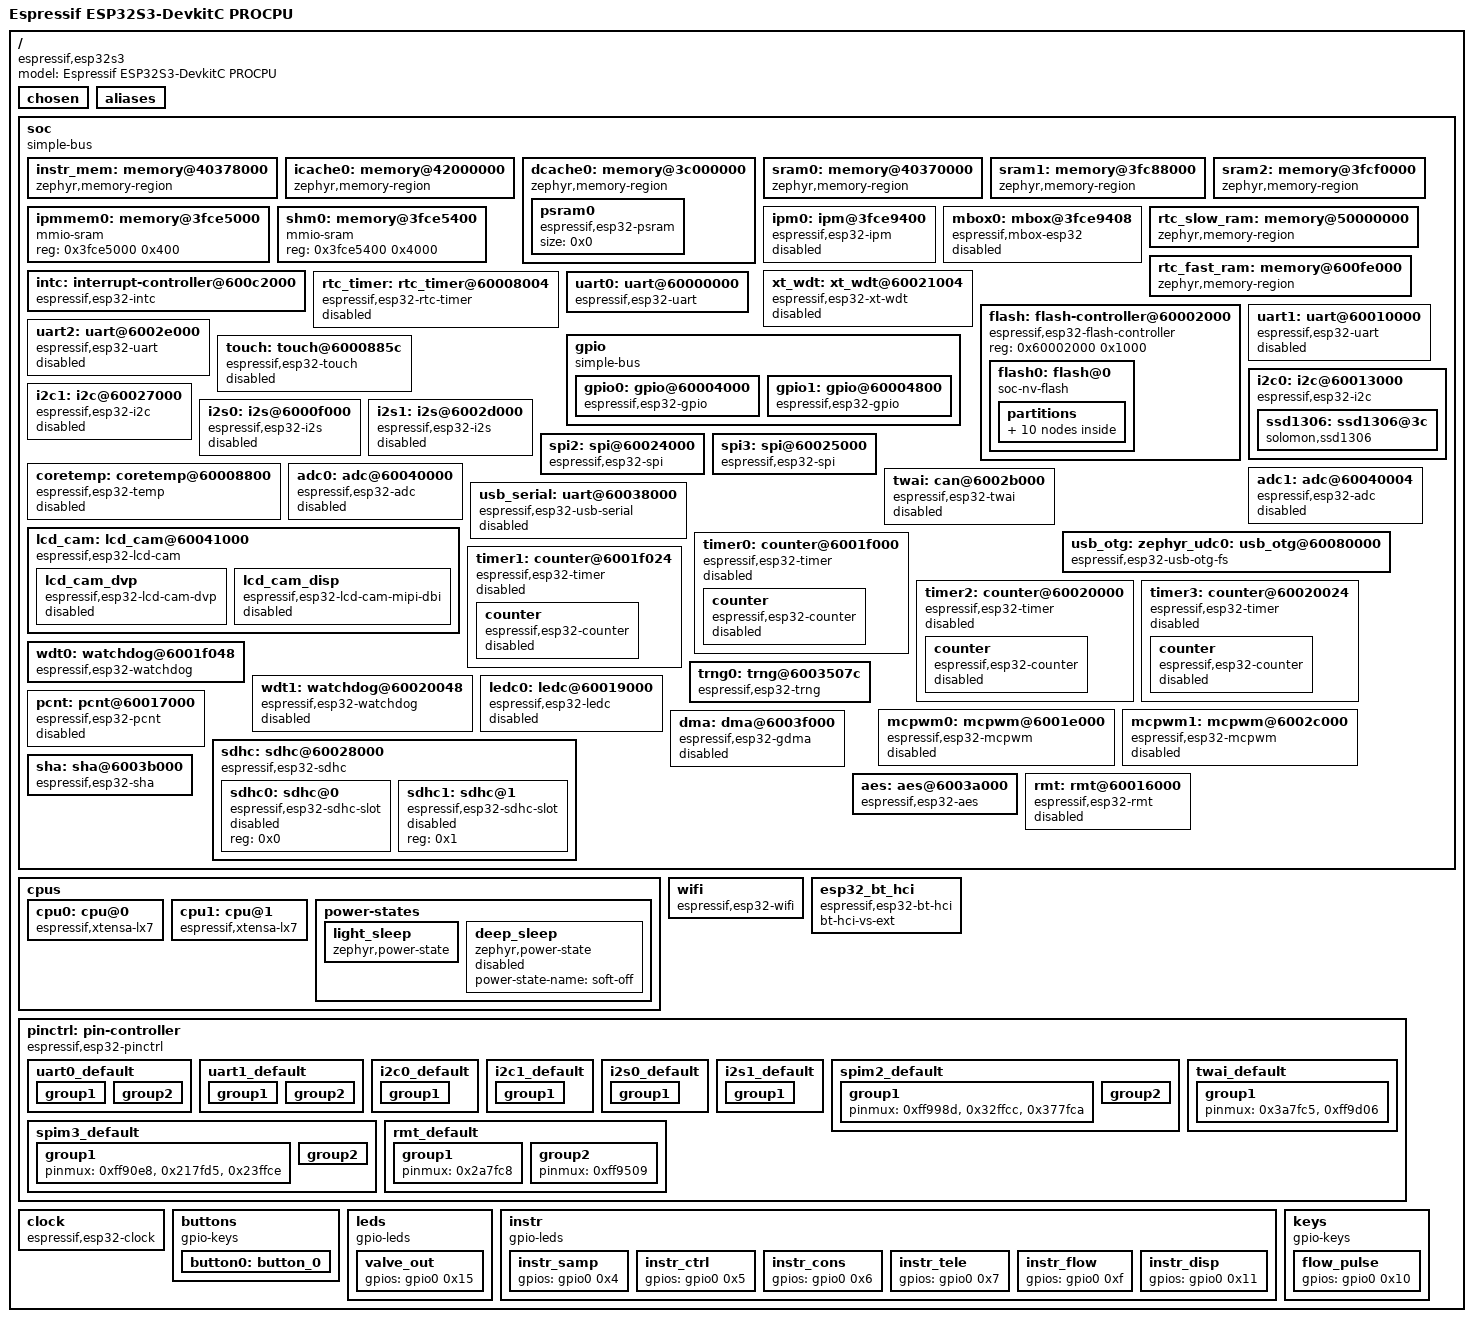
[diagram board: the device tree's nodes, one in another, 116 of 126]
/dts-v1/;

/* node '/' defined in zephyr/dts/common/skeleton.dtsi:9 */
/ {
	#address-cells = < 0x1 >;                   /* in zephyr/dts/common/skeleton.dtsi:10 */
	#size-cells = < 0x1 >;                      /* in zephyr/dts/common/skeleton.dtsi:11 */
	model = "Espressif ESP32S3-DevkitC PROCPU"; /* in zephyr/boards/espressif/esp32s3_devkitc/esp32s3_devkitc_procpu.dts:15 */
	compatible = "espressif,esp32s3";           /* in zephyr/boards/espressif/esp32s3_devkitc/esp32s3_devkitc_procpu.dts:16 */

	/* node '/chosen' defined in zephyr/dts/common/skeleton.dtsi:13 */
	chosen {
		zephyr,canbus = &twai;                    /* in zephyr/dts/xtensa/espressif/esp32s3/esp32s3_common.dtsi:22 */
		zephyr,entropy = &trng0;                  /* in zephyr/dts/xtensa/espressif/esp32s3/esp32s3_common.dtsi:23 */
		zephyr,flash-controller = &flash;         /* in zephyr/dts/xtensa/espressif/esp32s3/esp32s3_common.dtsi:24 */
		zephyr,sram = &sram1;                     /* in zephyr/boards/espressif/esp32s3_devkitc/esp32s3_devkitc_procpu.dts:26 */
		zephyr,console = &uart0;                  /* in zephyr/boards/espressif/esp32s3_devkitc/esp32s3_devkitc_procpu.dts:27 */
		zephyr,shell-uart = &uart0;               /* in zephyr/boards/espressif/esp32s3_devkitc/esp32s3_devkitc_procpu.dts:28 */
		zephyr,flash = &flash0;                   /* in zephyr/boards/espressif/esp32s3_devkitc/esp32s3_devkitc_procpu.dts:29 */
		zephyr,code-partition = &slot0_partition; /* in zephyr/boards/espressif/esp32s3_devkitc/esp32s3_devkitc_procpu.dts:30 */
		zephyr,bt-hci = &esp32_bt_hci;            /* in zephyr/boards/espressif/esp32s3_devkitc/esp32s3_devkitc_procpu.dts:31 */
	};

	/* node '/aliases' defined in zephyr/dts/common/skeleton.dtsi:15 */
	aliases {
		die-temp0 = &coretemp; /* in zephyr/dts/xtensa/espressif/esp32s3/esp32s3_common.dtsi:18 */
		i2c-0 = &i2c0;         /* in zephyr/boards/espressif/esp32s3_devkitc/esp32s3_devkitc_procpu.dts:19 */
		watchdog0 = &wdt0;     /* in zephyr/boards/espressif/esp32s3_devkitc/esp32s3_devkitc_procpu.dts:20 */
		uart-0 = &uart0;       /* in zephyr/boards/espressif/esp32s3_devkitc/esp32s3_devkitc_procpu.dts:21 */
		sw0 = &button0;        /* in zephyr/boards/espressif/esp32s3_devkitc/esp32s3_devkitc_procpu.dts:22 */
		led0 = &valve_out;     /* in ../4101137-real-time-systems/firmware/superloop/boards/esp32s3_devkitc_esp32s3_procpu.overlay:16 */
	};

	/* node '/soc' defined in zephyr/dts/xtensa/xtensa.dtsi:10 */
	soc {
		#address-cells = < 0x1 >;  /* in zephyr/dts/xtensa/espressif/esp32s3/esp32s3_common.dtsi:97 */
		#size-cells = < 0x1 >;     /* in zephyr/dts/xtensa/espressif/esp32s3/esp32s3_common.dtsi:98 */
		compatible = "simple-bus"; /* in zephyr/dts/xtensa/espressif/esp32s3/esp32s3_common.dtsi:99 */
		ranges;                    /* in zephyr/dts/xtensa/espressif/esp32s3/esp32s3_common.dtsi:100 */

		/* node '/soc/memory@40378000' defined in zephyr/dts/xtensa/espressif/esp32s3/esp32s3_common.dtsi:102 */
		instr_mem: memory@40378000 {
			compatible = "zephyr,memory-region"; /* in zephyr/dts/xtensa/espressif/esp32s3/esp32s3_common.dtsi:103 */
			reg = < 0x40378000 0x68000 >;        /* in zephyr/dts/xtensa/espressif/esp32s3/esp32s3_common.dtsi:104 */
			zephyr,memory-region = "IRAM";       /* in zephyr/dts/xtensa/espressif/esp32s3/esp32s3_common.dtsi:105 */
		};

		/* node '/soc/memory@42000000' defined in zephyr/dts/xtensa/espressif/esp32s3/esp32s3_common.dtsi:108 */
		icache0: memory@42000000 {
			compatible = "zephyr,memory-region"; /* in zephyr/dts/xtensa/espressif/esp32s3/esp32s3_common.dtsi:109 */
			reg = < 0x42000000 0x2000000 >;      /* in zephyr/dts/xtensa/espressif/esp32s3/esp32s3_common.dtsi:110 */
			zephyr,memory-region = "ICACHE0";    /* in zephyr/dts/xtensa/espressif/esp32s3/esp32s3_common.dtsi:111 */
		};

		/* node '/soc/memory@3c000000' defined in zephyr/dts/xtensa/espressif/esp32s3/esp32s3_common.dtsi:114 */
		dcache0: memory@3c000000 {
			compatible = "zephyr,memory-region"; /* in zephyr/dts/xtensa/espressif/esp32s3/esp32s3_common.dtsi:115 */
			reg = < 0x3c000000 0x2000000 >;      /* in zephyr/dts/xtensa/espressif/esp32s3/esp32s3_common.dtsi:116 */
			zephyr,memory-region = "DCACHE0";    /* in zephyr/dts/xtensa/espressif/esp32s3/esp32s3_common.dtsi:117 */

			/* node '/soc/memory@3c000000/psram0' defined in zephyr/dts/xtensa/espressif/esp32s3/esp32s3_common.dtsi:119 */
			psram0: psram0 {
				compatible = "espressif,esp32-psram"; /* in zephyr/dts/xtensa/espressif/esp32s3/esp32s3_common.dtsi:120 */
				size = < 0x0 >;                       /* in zephyr/dts/xtensa/espressif/esp32s3/esp32s3_common.dtsi:121 */
			};
		};

		/* node '/soc/memory@40370000' defined in zephyr/dts/xtensa/espressif/esp32s3/esp32s3_common.dtsi:125 */
		sram0: memory@40370000 {
			compatible = "zephyr,memory-region",
			             "mmio-sram";            /* in zephyr/dts/xtensa/espressif/esp32s3/esp32s3_common.dtsi:126 */
			reg = < 0x40370000 0x8000 >;         /* in zephyr/dts/xtensa/espressif/esp32s3/esp32s3_common.dtsi:127 */
			zephyr,memory-region = "SRAM0";      /* in zephyr/dts/xtensa/espressif/esp32s3/esp32s3_common.dtsi:128 */
		};

		/* node '/soc/memory@3fc88000' defined in zephyr/dts/xtensa/espressif/esp32s3/esp32s3_common.dtsi:131 */
		sram1: memory@3fc88000 {
			compatible = "zephyr,memory-region",
			             "mmio-sram";            /* in zephyr/dts/xtensa/espressif/esp32s3/esp32s3_common.dtsi:132 */
			reg = < 0x3fc88000 0x68000 >;        /* in zephyr/dts/xtensa/espressif/esp32s3/esp32s3_common.dtsi:133 */
			zephyr,memory-region = "SRAM1";      /* in zephyr/dts/xtensa/espressif/esp32s3/esp32s3_common.dtsi:134 */
		};

		/* node '/soc/memory@3fcf0000' defined in zephyr/dts/xtensa/espressif/esp32s3/esp32s3_common.dtsi:137 */
		sram2: memory@3fcf0000 {
			compatible = "zephyr,memory-region",
			             "mmio-sram";            /* in zephyr/dts/xtensa/espressif/esp32s3/esp32s3_common.dtsi:138 */
			reg = < 0x3fcf0000 0x10000 >;        /* in zephyr/dts/xtensa/espressif/esp32s3/esp32s3_common.dtsi:139 */
			zephyr,memory-region = "SRAM2";      /* in zephyr/dts/xtensa/espressif/esp32s3/esp32s3_common.dtsi:140 */
		};

		/* node '/soc/memory@3fce5000' defined in zephyr/dts/xtensa/espressif/esp32s3/esp32s3_common.dtsi:143 */
		ipmmem0: memory@3fce5000 {
			compatible = "mmio-sram";   /* in zephyr/dts/xtensa/espressif/esp32s3/esp32s3_common.dtsi:144 */
			reg = < 0x3fce5000 0x400 >; /* in zephyr/dts/xtensa/espressif/esp32s3/esp32s3_common.dtsi:145 */
			phandle = < 0x1 >;          /* in zephyr/dts/xtensa/espressif/esp32s3/esp32s3_common.dtsi:157 */
		};

		/* node '/soc/memory@3fce5400' defined in zephyr/dts/xtensa/espressif/esp32s3/esp32s3_common.dtsi:148 */
		shm0: memory@3fce5400 {
			compatible = "mmio-sram";    /* in zephyr/dts/xtensa/espressif/esp32s3/esp32s3_common.dtsi:149 */
			reg = < 0x3fce5400 0x4000 >; /* in zephyr/dts/xtensa/espressif/esp32s3/esp32s3_common.dtsi:150 */
		};

		/* node '/soc/ipm@3fce9400' defined in zephyr/dts/xtensa/espressif/esp32s3/esp32s3_common.dtsi:153 */
		ipm0: ipm@3fce9400 {
			compatible = "espressif,esp32-ipm"; /* in zephyr/dts/xtensa/espressif/esp32s3/esp32s3_common.dtsi:154 */
			reg = < 0x3fce9400 0x8 >;           /* in zephyr/dts/xtensa/espressif/esp32s3/esp32s3_common.dtsi:155 */
			status = "disabled";                /* in zephyr/dts/xtensa/espressif/esp32s3/esp32s3_common.dtsi:156 */
			shared-memory = < &ipmmem0 >;       /* in zephyr/dts/xtensa/espressif/esp32s3/esp32s3_common.dtsi:157 */
			shared-memory-size = < 0x400 >;     /* in zephyr/dts/xtensa/espressif/esp32s3/esp32s3_common.dtsi:158 */
			interrupts = < 0x4f 0x0 0x0 >,
			             < 0x50 0x0 0x0 >;      /* in zephyr/dts/xtensa/espressif/esp32s3/esp32s3_common.dtsi:159 */
			interrupt-parent = < &intc >;       /* in zephyr/dts/xtensa/espressif/esp32s3/esp32s3_common.dtsi:161 */
		};

		/* node '/soc/mbox@3fce9408' defined in zephyr/dts/xtensa/espressif/esp32s3/esp32s3_common.dtsi:164 */
		mbox0: mbox@3fce9408 {
			compatible = "espressif,mbox-esp32"; /* in zephyr/dts/xtensa/espressif/esp32s3/esp32s3_common.dtsi:165 */
			reg = < 0x3fce9408 0x8 >;            /* in zephyr/dts/xtensa/espressif/esp32s3/esp32s3_common.dtsi:166 */
			status = "disabled";                 /* in zephyr/dts/xtensa/espressif/esp32s3/esp32s3_common.dtsi:167 */
			shared-memory = < &ipmmem0 >;        /* in zephyr/dts/xtensa/espressif/esp32s3/esp32s3_common.dtsi:168 */
			shared-memory-size = < 0x400 >;      /* in zephyr/dts/xtensa/espressif/esp32s3/esp32s3_common.dtsi:169 */
			interrupts = < 0x4f 0x0 0x0 >,
			             < 0x50 0x0 0x0 >;       /* in zephyr/dts/xtensa/espressif/esp32s3/esp32s3_common.dtsi:170 */
			interrupt-parent = < &intc >;        /* in zephyr/dts/xtensa/espressif/esp32s3/esp32s3_common.dtsi:172 */
			#mbox-cells = < 0x1 >;               /* in zephyr/dts/xtensa/espressif/esp32s3/esp32s3_common.dtsi:173 */
		};

		/* node '/soc/memory@50000000' defined in zephyr/dts/xtensa/espressif/esp32s3/esp32s3_common.dtsi:176 */
		rtc_slow_ram: memory@50000000 {
			compatible = "zephyr,memory-region",
			             "mmio-sram";              /* in zephyr/dts/xtensa/espressif/esp32s3/esp32s3_common.dtsi:177 */
			reg = < 0x50000000 0x2000 >;           /* in zephyr/dts/xtensa/espressif/esp32s3/esp32s3_common.dtsi:178 */
			zephyr,memory-region = "RTC_SLOW_RAM"; /* in zephyr/dts/xtensa/espressif/esp32s3/esp32s3_common.dtsi:179 */
		};

		/* node '/soc/memory@600fe000' defined in zephyr/dts/xtensa/espressif/esp32s3/esp32s3_common.dtsi:182 */
		rtc_fast_ram: memory@600fe000 {
			compatible = "zephyr,memory-region",
			             "mmio-sram";              /* in zephyr/dts/xtensa/espressif/esp32s3/esp32s3_common.dtsi:183 */
			reg = < 0x600fe000 0x2000 >;           /* in zephyr/dts/xtensa/espressif/esp32s3/esp32s3_common.dtsi:184 */
			zephyr,memory-region = "RTC_FAST_RAM"; /* in zephyr/dts/xtensa/espressif/esp32s3/esp32s3_common.dtsi:185 */
		};

		/* node '/soc/interrupt-controller@600c2000' defined in zephyr/dts/xtensa/espressif/esp32s3/esp32s3_common.dtsi:188 */
		intc: interrupt-controller@600c2000 {
			#interrupt-cells = < 0x3 >;          /* in zephyr/dts/xtensa/espressif/esp32s3/esp32s3_common.dtsi:189 */
			#address-cells = < 0x0 >;            /* in zephyr/dts/xtensa/espressif/esp32s3/esp32s3_common.dtsi:190 */
			compatible = "espressif,esp32-intc"; /* in zephyr/dts/xtensa/espressif/esp32s3/esp32s3_common.dtsi:191 */
			interrupt-controller;                /* in zephyr/dts/xtensa/espressif/esp32s3/esp32s3_common.dtsi:192 */
			reg = < 0x600c2000 0x1000 >;         /* in zephyr/dts/xtensa/espressif/esp32s3/esp32s3_common.dtsi:193 */
			status = "okay";                     /* in zephyr/dts/xtensa/espressif/esp32s3/esp32s3_common.dtsi:194 */
			phandle = < 0x2 >;                   /* in zephyr/dts/xtensa/espressif/esp32s3/esp32s3_common.dtsi:161 */
		};

		/* node '/soc/xt_wdt@60021004' defined in zephyr/dts/xtensa/espressif/esp32s3/esp32s3_common.dtsi:197 */
		xt_wdt: xt_wdt@60021004 {
			compatible = "espressif,esp32-xt-wdt"; /* in zephyr/dts/xtensa/espressif/esp32s3/esp32s3_common.dtsi:198 */
			reg = < 0x60021004 0x4 >;              /* in zephyr/dts/xtensa/espressif/esp32s3/esp32s3_common.dtsi:199 */
			clocks = < &clock 0xc >;               /* in zephyr/dts/xtensa/espressif/esp32s3/esp32s3_common.dtsi:200 */
			interrupts = < 0x27 0x0 0x0 >;         /* in zephyr/dts/xtensa/espressif/esp32s3/esp32s3_common.dtsi:201 */
			interrupt-parent = < &intc >;          /* in zephyr/dts/xtensa/espressif/esp32s3/esp32s3_common.dtsi:202 */
			status = "disabled";                   /* in zephyr/dts/xtensa/espressif/esp32s3/esp32s3_common.dtsi:203 */
		};

		/* node '/soc/rtc_timer@60008004' defined in zephyr/dts/xtensa/espressif/esp32s3/esp32s3_common.dtsi:206 */
		rtc_timer: rtc_timer@60008004 {
			reg = < 0x60008004 0xc >;                 /* in zephyr/dts/xtensa/espressif/esp32s3/esp32s3_common.dtsi:207 */
			compatible = "espressif,esp32-rtc-timer"; /* in zephyr/dts/xtensa/espressif/esp32s3/esp32s3_common.dtsi:208 */
			clocks = < &clock 0xc >;                  /* in zephyr/dts/xtensa/espressif/esp32s3/esp32s3_common.dtsi:209 */
			interrupts = < 0x27 0x0 0x0 >;            /* in zephyr/dts/xtensa/espressif/esp32s3/esp32s3_common.dtsi:210 */
			interrupt-parent = < &intc >;             /* in zephyr/dts/xtensa/espressif/esp32s3/esp32s3_common.dtsi:211 */
			status = "disabled";                      /* in zephyr/dts/xtensa/espressif/esp32s3/esp32s3_common.dtsi:212 */
		};

		/* node '/soc/flash-controller@60002000' defined in zephyr/dts/xtensa/espressif/esp32s3/esp32s3_common.dtsi:215 */
		flash: flash-controller@60002000 {
			compatible = "espressif,esp32-flash-controller"; /* in zephyr/dts/xtensa/espressif/esp32s3/esp32s3_common.dtsi:216 */
			reg = < 0x60002000 0x1000 >;                     /* in zephyr/dts/xtensa/espressif/esp32s3/esp32s3_common.dtsi:217 */
			#address-cells = < 0x1 >;                        /* in zephyr/dts/xtensa/espressif/esp32s3/esp32s3_common.dtsi:218 */
			#size-cells = < 0x1 >;                           /* in zephyr/dts/xtensa/espressif/esp32s3/esp32s3_common.dtsi:219 */
			ranges;                                          /* in zephyr/dts/xtensa/espressif/esp32s3/esp32s3_common.dtsi:220 */

			/* node '/soc/flash-controller@60002000/flash@0' defined in zephyr/dts/xtensa/espressif/esp32s3/esp32s3_common.dtsi:222 */
			flash0: flash@0 {
				compatible = "soc-nv-flash";   /* in zephyr/dts/xtensa/espressif/esp32s3/esp32s3_common.dtsi:223 */
				erase-block-size = < 0x1000 >; /* in zephyr/dts/xtensa/espressif/esp32s3/esp32s3_common.dtsi:224 */
				write-block-size = < 0x4 >;    /* in zephyr/dts/xtensa/espressif/esp32s3/esp32s3_common.dtsi:225 */
				#address-cells = < 0x1 >;      /* in zephyr/dts/xtensa/espressif/esp32s3/esp32s3_common.dtsi:226 */
				#size-cells = < 0x1 >;         /* in zephyr/dts/xtensa/espressif/esp32s3/esp32s3_common.dtsi:227 */
				reg = < 0x0 0x800000 >;        /* in zephyr/dts/xtensa/espressif/esp32s3/esp32s3_wroom_n8.dtsi:11 */
				ranges = < 0x0 0x0 0x800000 >; /* in zephyr/dts/xtensa/espressif/esp32s3/esp32s3_wroom_n8.dtsi:12 */

				/* node '/soc/flash-controller@60002000/flash@0/partitions' defined in zephyr/dts/vendor/espressif/partitions_0x0_amp_4M.dtsi:8 */
				partitions {
					ranges;                   /* in zephyr/dts/vendor/espressif/partitions_0x0_amp_4M.dtsi:9 */
					#address-cells = < 0x1 >; /* in zephyr/dts/vendor/espressif/partitions_0x0_amp_4M.dtsi:10 */
					#size-cells = < 0x1 >;    /* in zephyr/dts/vendor/espressif/partitions_0x0_amp_4M.dtsi:11 */

					/* node '/soc/flash-controller@60002000/flash@0/partitions/partition@0' defined in zephyr/dts/vendor/espressif/partitions_0x0_amp_4M.dtsi:13 */
					boot_partition: partition@0 {
						compatible = "zephyr,mapped-partition"; /* in zephyr/dts/vendor/espressif/partitions_0x0_amp_4M.dtsi:14 */
						label = "mcuboot";                      /* in zephyr/dts/vendor/espressif/partitions_0x0_amp_4M.dtsi:15 */
						reg = < 0x0 0x10000 >;                  /* in zephyr/dts/vendor/espressif/partitions_0x0_amp_4M.dtsi:16 */
					};

					/* node '/soc/flash-controller@60002000/flash@0/partitions/partition@10000' defined in zephyr/dts/vendor/espressif/partitions_0x0_amp_4M.dtsi:19 */
					sys_partition: partition@10000 {
						compatible = "zephyr,mapped-partition"; /* in zephyr/dts/vendor/espressif/partitions_0x0_amp_4M.dtsi:20 */
						label = "sys";                          /* in zephyr/dts/vendor/espressif/partitions_0x0_amp_4M.dtsi:21 */
						reg = < 0x10000 0x10000 >;              /* in zephyr/dts/vendor/espressif/partitions_0x0_amp_4M.dtsi:22 */
					};

					/* node '/soc/flash-controller@60002000/flash@0/partitions/partition@20000' defined in zephyr/dts/vendor/espressif/partitions_0x0_amp_4M.dtsi:25 */
					slot0_partition: partition@20000 {
						compatible = "zephyr,mapped-partition"; /* in zephyr/dts/vendor/espressif/partitions_0x0_amp_4M.dtsi:26 */
						label = "image-0";                      /* in zephyr/dts/vendor/espressif/partitions_0x0_amp_4M.dtsi:27 */
						reg = < 0x20000 0x150000 >;             /* in zephyr/dts/vendor/espressif/partitions_0x0_amp_4M.dtsi:28 */
					};

					/* node '/soc/flash-controller@60002000/flash@0/partitions/partition@170000' defined in zephyr/dts/vendor/espressif/partitions_0x0_amp_4M.dtsi:31 */
					slot1_partition: partition@170000 {
						compatible = "zephyr,mapped-partition"; /* in zephyr/dts/vendor/espressif/partitions_0x0_amp_4M.dtsi:32 */
						label = "image-1";                      /* in zephyr/dts/vendor/espressif/partitions_0x0_amp_4M.dtsi:33 */
						reg = < 0x170000 0x150000 >;            /* in zephyr/dts/vendor/espressif/partitions_0x0_amp_4M.dtsi:34 */
					};

					/* node '/soc/flash-controller@60002000/flash@0/partitions/partition@2c0000' defined in zephyr/dts/vendor/espressif/partitions_0x0_amp_4M.dtsi:37 */
					slot0_appcpu_partition: partition@2c0000 {
						compatible = "zephyr,mapped-partition"; /* in zephyr/dts/vendor/espressif/partitions_0x0_amp_4M.dtsi:38 */
						label = "image-0-appcpu";               /* in zephyr/dts/vendor/espressif/partitions_0x0_amp_4M.dtsi:39 */
						reg = < 0x2c0000 0x70000 >;             /* in zephyr/dts/vendor/espressif/partitions_0x0_amp_4M.dtsi:40 */
					};

					/* node '/soc/flash-controller@60002000/flash@0/partitions/partition@330000' defined in zephyr/dts/vendor/espressif/partitions_0x0_amp_4M.dtsi:43 */
					slot1_appcpu_partition: partition@330000 {
						compatible = "zephyr,mapped-partition"; /* in zephyr/dts/vendor/espressif/partitions_0x0_amp_4M.dtsi:44 */
						label = "image-1-appcpu";               /* in zephyr/dts/vendor/espressif/partitions_0x0_amp_4M.dtsi:45 */
						reg = < 0x330000 0x70000 >;             /* in zephyr/dts/vendor/espressif/partitions_0x0_amp_4M.dtsi:46 */
					};

					/* node '/soc/flash-controller@60002000/flash@0/partitions/partition@3a0000' defined in zephyr/dts/vendor/espressif/partitions_0x0_amp_4M.dtsi:49 */
					slot0_lpcore_partition: partition@3a0000 {
						compatible = "zephyr,mapped-partition"; /* in zephyr/dts/vendor/espressif/partitions_0x0_amp_4M.dtsi:50 */
						label = "image-0-lpcore";               /* in zephyr/dts/vendor/espressif/partitions_0x0_amp_4M.dtsi:51 */
						reg = < 0x3a0000 0x8000 >;              /* in zephyr/dts/vendor/espressif/partitions_0x0_amp_4M.dtsi:52 */
					};

					/* node '/soc/flash-controller@60002000/flash@0/partitions/partition@3a8000' defined in zephyr/dts/vendor/espressif/partitions_0x0_amp_4M.dtsi:55 */
					slot1_lpcore_partition: partition@3a8000 {
						compatible = "zephyr,mapped-partition"; /* in zephyr/dts/vendor/espressif/partitions_0x0_amp_4M.dtsi:56 */
						label = "image-1-lpcore";               /* in zephyr/dts/vendor/espressif/partitions_0x0_amp_4M.dtsi:57 */
						reg = < 0x3a8000 0x8000 >;              /* in zephyr/dts/vendor/espressif/partitions_0x0_amp_4M.dtsi:58 */
					};

					/* node '/soc/flash-controller@60002000/flash@0/partitions/partition@3b0000' defined in zephyr/dts/vendor/espressif/partitions_0x0_amp_4M.dtsi:61 */
					storage_partition: partition@3b0000 {
						compatible = "zephyr,mapped-partition"; /* in zephyr/dts/vendor/espressif/partitions_0x0_amp_4M.dtsi:62 */
						label = "storage";                      /* in zephyr/dts/vendor/espressif/partitions_0x0_amp_4M.dtsi:63 */
						reg = < 0x3b0000 0x30000 >;             /* in zephyr/dts/vendor/espressif/partitions_0x0_amp_4M.dtsi:64 */
					};

					/* node '/soc/flash-controller@60002000/flash@0/partitions/partition@3ff000' defined in zephyr/dts/vendor/espressif/partitions_0x0_amp_4M.dtsi:67 */
					coredump_partition: partition@3ff000 {
						compatible = "zephyr,mapped-partition"; /* in zephyr/dts/vendor/espressif/partitions_0x0_amp_4M.dtsi:68 */
						label = "coredump";                     /* in zephyr/dts/vendor/espressif/partitions_0x0_amp_4M.dtsi:69 */
						reg = < 0x3ff000 0x1000 >;              /* in zephyr/dts/vendor/espressif/partitions_0x0_amp_4M.dtsi:70 */
					};
				};
			};
		};

		/* node '/soc/uart@60000000' defined in zephyr/dts/xtensa/espressif/esp32s3/esp32s3_common.dtsi:232 */
		uart0: uart@60000000 {
			compatible = "espressif,esp32-uart"; /* in zephyr/dts/xtensa/espressif/esp32s3/esp32s3_common.dtsi:233 */
			reg = < 0x60000000 0x1000 >;         /* in zephyr/dts/xtensa/espressif/esp32s3/esp32s3_common.dtsi:234 */
			interrupts = < 0x1b 0x0 0x0 >;       /* in zephyr/dts/xtensa/espressif/esp32s3/esp32s3_common.dtsi:235 */
			interrupt-parent = < &intc >;        /* in zephyr/dts/xtensa/espressif/esp32s3/esp32s3_common.dtsi:236 */
			clocks = < &clock 0x65 >;            /* in zephyr/dts/xtensa/espressif/esp32s3/esp32s3_common.dtsi:237 */
			status = "okay";                     /* in zephyr/boards/espressif/esp32s3_devkitc/esp32s3_devkitc_procpu.dts:50 */
			current-speed = < 0x1c200 >;         /* in zephyr/boards/espressif/esp32s3_devkitc/esp32s3_devkitc_procpu.dts:51 */
			pinctrl-0 = < &uart0_default >;      /* in zephyr/boards/espressif/esp32s3_devkitc/esp32s3_devkitc_procpu.dts:52 */
			pinctrl-names = "default";           /* in zephyr/boards/espressif/esp32s3_devkitc/esp32s3_devkitc_procpu.dts:53 */
		};

		/* node '/soc/uart@60010000' defined in zephyr/dts/xtensa/espressif/esp32s3/esp32s3_common.dtsi:241 */
		uart1: uart@60010000 {
			compatible = "espressif,esp32-uart"; /* in zephyr/dts/xtensa/espressif/esp32s3/esp32s3_common.dtsi:242 */
			reg = < 0x60010000 0x1000 >;         /* in zephyr/dts/xtensa/espressif/esp32s3/esp32s3_common.dtsi:243 */
			interrupts = < 0x1c 0x0 0x0 >;       /* in zephyr/dts/xtensa/espressif/esp32s3/esp32s3_common.dtsi:244 */
			interrupt-parent = < &intc >;        /* in zephyr/dts/xtensa/espressif/esp32s3/esp32s3_common.dtsi:245 */
			clocks = < &clock 0x0 >;             /* in zephyr/dts/xtensa/espressif/esp32s3/esp32s3_common.dtsi:246 */
			status = "disabled";                 /* in zephyr/dts/xtensa/espressif/esp32s3/esp32s3_common.dtsi:247 */
		};

		/* node '/soc/uart@6002e000' defined in zephyr/dts/xtensa/espressif/esp32s3/esp32s3_common.dtsi:250 */
		uart2: uart@6002e000 {
			compatible = "espressif,esp32-uart"; /* in zephyr/dts/xtensa/espressif/esp32s3/esp32s3_common.dtsi:251 */
			reg = < 0x6002e000 0x1000 >;         /* in zephyr/dts/xtensa/espressif/esp32s3/esp32s3_common.dtsi:252 */
			interrupts = < 0x1d 0x0 0x0 >;       /* in zephyr/dts/xtensa/espressif/esp32s3/esp32s3_common.dtsi:253 */
			interrupt-parent = < &intc >;        /* in zephyr/dts/xtensa/espressif/esp32s3/esp32s3_common.dtsi:254 */
			clocks = < &clock 0x1 >;             /* in zephyr/dts/xtensa/espressif/esp32s3/esp32s3_common.dtsi:255 */
			status = "disabled";                 /* in zephyr/dts/xtensa/espressif/esp32s3/esp32s3_common.dtsi:256 */
		};

		/* node '/soc/gpio' defined in zephyr/dts/xtensa/espressif/esp32s3/esp32s3_common.dtsi:259 */
		gpio: gpio {
			compatible = "simple-bus";                                     /* in zephyr/dts/xtensa/espressif/esp32s3/esp32s3_common.dtsi:260 */
			gpio-map-mask = < 0xffffffe0 0xffffffc0 >;                     /* in zephyr/dts/xtensa/espressif/esp32s3/esp32s3_common.dtsi:261 */
			gpio-map-pass-thru = < 0x1f 0x3f >;                            /* in zephyr/dts/xtensa/espressif/esp32s3/esp32s3_common.dtsi:262 */
			gpio-map = < 0x0 0x0 &gpio0 0x0 0x0 0x20 0x0 &gpio1 0x0 0x0 >; /* in zephyr/dts/xtensa/espressif/esp32s3/esp32s3_common.dtsi:263 */
			#gpio-cells = < 0x2 >;                                         /* in zephyr/dts/xtensa/espressif/esp32s3/esp32s3_common.dtsi:265 */
			#address-cells = < 0x1 >;                                      /* in zephyr/dts/xtensa/espressif/esp32s3/esp32s3_common.dtsi:266 */
			#size-cells = < 0x1 >;                                         /* in zephyr/dts/xtensa/espressif/esp32s3/esp32s3_common.dtsi:267 */
			ranges;                                                        /* in zephyr/dts/xtensa/espressif/esp32s3/esp32s3_common.dtsi:268 */

			/* node '/soc/gpio/gpio@60004000' defined in zephyr/dts/xtensa/espressif/esp32s3/esp32s3_common.dtsi:270 */
			gpio0: gpio@60004000 {
				compatible = "espressif,esp32-gpio"; /* in zephyr/dts/xtensa/espressif/esp32s3/esp32s3_common.dtsi:271 */
				gpio-controller;                     /* in zephyr/dts/xtensa/espressif/esp32s3/esp32s3_common.dtsi:272 */
				#gpio-cells = < 0x2 >;               /* in zephyr/dts/xtensa/espressif/esp32s3/esp32s3_common.dtsi:273 */
				reg = < 0x60004000 0x800 >;          /* in zephyr/dts/xtensa/espressif/esp32s3/esp32s3_common.dtsi:274 */
				interrupts = < 0x10 0x0 0x0 >;       /* in zephyr/dts/xtensa/espressif/esp32s3/esp32s3_common.dtsi:275 */
				interrupt-parent = < &intc >;        /* in zephyr/dts/xtensa/espressif/esp32s3/esp32s3_common.dtsi:276 */
				ngpios = < 0x20 >;                   /* in zephyr/dts/xtensa/espressif/esp32s3/esp32s3_common.dtsi:282 */
				status = "okay";                     /* in zephyr/boards/espressif/esp32s3_devkitc/esp32s3_devkitc_procpu.dts:57 */
				phandle = < 0x5 >;                   /* in zephyr/dts/xtensa/espressif/esp32s3/esp32s3_common.dtsi:263 */
			};

			/* node '/soc/gpio/gpio@60004800' defined in zephyr/dts/xtensa/espressif/esp32s3/esp32s3_common.dtsi:285 */
			gpio1: gpio@60004800 {
				compatible = "espressif,esp32-gpio"; /* in zephyr/dts/xtensa/espressif/esp32s3/esp32s3_common.dtsi:286 */
				gpio-controller;                     /* in zephyr/dts/xtensa/espressif/esp32s3/esp32s3_common.dtsi:287 */
				#gpio-cells = < 0x2 >;               /* in zephyr/dts/xtensa/espressif/esp32s3/esp32s3_common.dtsi:288 */
				reg = < 0x60004800 0x800 >;          /* in zephyr/dts/xtensa/espressif/esp32s3/esp32s3_common.dtsi:289 */
				interrupts = < 0x10 0x0 0x0 >;       /* in zephyr/dts/xtensa/espressif/esp32s3/esp32s3_common.dtsi:290 */
				interrupt-parent = < &intc >;        /* in zephyr/dts/xtensa/espressif/esp32s3/esp32s3_common.dtsi:291 */
				ngpios = < 0x16 >;                   /* in zephyr/dts/xtensa/espressif/esp32s3/esp32s3_common.dtsi:292 */
				status = "okay";                     /* in zephyr/boards/espressif/esp32s3_devkitc/esp32s3_devkitc_procpu.dts:61 */
				phandle = < 0x6 >;                   /* in zephyr/dts/xtensa/espressif/esp32s3/esp32s3_common.dtsi:263 */
			};
		};

		/* node '/soc/touch@6000885c' defined in zephyr/dts/xtensa/espressif/esp32s3/esp32s3_common.dtsi:296 */
		touch: touch@6000885c {
			compatible = "espressif,esp32-touch";      /* in zephyr/dts/xtensa/espressif/esp32s3/esp32s3_common.dtsi:297 */
			reg = < 0x6000885c 0x88 0x60008908 0x18 >; /* in zephyr/dts/xtensa/espressif/esp32s3/esp32s3_common.dtsi:298 */
			interrupts = < 0x27 0x0 0x0 >;             /* in zephyr/dts/xtensa/espressif/esp32s3/esp32s3_common.dtsi:299 */
			interrupt-parent = < &intc >;              /* in zephyr/dts/xtensa/espressif/esp32s3/esp32s3_common.dtsi:300 */
			status = "disabled";                       /* in zephyr/dts/xtensa/espressif/esp32s3/esp32s3_common.dtsi:301 */
			debounce-interval-ms = < 0x1e >;           /* in zephyr/boards/espressif/esp32s3_devkitc/esp32s3_devkitc_procpu.dts:65 */
			href-microvolt = < 0x2932e0 >;             /* in zephyr/boards/espressif/esp32s3_devkitc/esp32s3_devkitc_procpu.dts:66 */
			lref-microvolt = < 0x7a120 >;              /* in zephyr/boards/espressif/esp32s3_devkitc/esp32s3_devkitc_procpu.dts:67 */
			href-atten-microvolt = < 0xf4240 >;        /* in zephyr/boards/espressif/esp32s3_devkitc/esp32s3_devkitc_procpu.dts:68 */
			filter-mode = < 0x2 >;                     /* in zephyr/boards/espressif/esp32s3_devkitc/esp32s3_devkitc_procpu.dts:69 */
			filter-debounce-cnt = < 0x1 >;             /* in zephyr/boards/espressif/esp32s3_devkitc/esp32s3_devkitc_procpu.dts:70 */
			filter-noise-thr = < 0x0 >;                /* in zephyr/boards/espressif/esp32s3_devkitc/esp32s3_devkitc_procpu.dts:71 */
			filter-jitter-step = < 0x4 >;              /* in zephyr/boards/espressif/esp32s3_devkitc/esp32s3_devkitc_procpu.dts:72 */
			filter-smooth-level = < 0x1 >;             /* in zephyr/boards/espressif/esp32s3_devkitc/esp32s3_devkitc_procpu.dts:73 */
		};

		/* node '/soc/i2c@60013000' defined in zephyr/dts/xtensa/espressif/esp32s3/esp32s3_common.dtsi:304 */
		i2c0: i2c@60013000 {
			compatible = "espressif,esp32-i2c"; /* in zephyr/dts/xtensa/espressif/esp32s3/esp32s3_common.dtsi:305 */
			#address-cells = < 0x1 >;           /* in zephyr/dts/xtensa/espressif/esp32s3/esp32s3_common.dtsi:306 */
			#size-cells = < 0x0 >;              /* in zephyr/dts/xtensa/espressif/esp32s3/esp32s3_common.dtsi:307 */
			reg = < 0x60013000 0x1000 >;        /* in zephyr/dts/xtensa/espressif/esp32s3/esp32s3_common.dtsi:308 */
			interrupts = < 0x2a 0x0 0x0 >;      /* in zephyr/dts/xtensa/espressif/esp32s3/esp32s3_common.dtsi:309 */
			interrupt-parent = < &intc >;       /* in zephyr/dts/xtensa/espressif/esp32s3/esp32s3_common.dtsi:310 */
			clocks = < &clock 0x67 >;           /* in zephyr/dts/xtensa/espressif/esp32s3/esp32s3_common.dtsi:311 */
			pinctrl-0 = < &i2c0_default >;      /* in zephyr/boards/espressif/esp32s3_devkitc/esp32s3_devkitc_procpu.dts:78 */
			pinctrl-names = "default";          /* in zephyr/boards/espressif/esp32s3_devkitc/esp32s3_devkitc_procpu.dts:79 */
			status = "okay";                    /* in ../4101137-real-time-systems/firmware/superloop/boards/esp32s3_devkitc_esp32s3_procpu.overlay:45 */
			clock-frequency = < 0x61a80 >;      /* in ../4101137-real-time-systems/firmware/superloop/boards/esp32s3_devkitc_esp32s3_procpu.overlay:46 */

			/* node '/soc/i2c@60013000/ssd1306@3c' defined in ../4101137-real-time-systems/firmware/superloop/boards/esp32s3_devkitc_esp32s3_procpu.overlay:48 */
			ssd1306: ssd1306@3c {
				compatible = "solomon,ssd1306"; /* in ../4101137-real-time-systems/firmware/superloop/boards/esp32s3_devkitc_esp32s3_procpu.overlay:49 */
				reg = < 0x3c >;                 /* in ../4101137-real-time-systems/firmware/superloop/boards/esp32s3_devkitc_esp32s3_procpu.overlay:50 */
				width = < 0x80 >;               /* in ../4101137-real-time-systems/firmware/superloop/boards/esp32s3_devkitc_esp32s3_procpu.overlay:51 */
				height = < 0x40 >;              /* in ../4101137-real-time-systems/firmware/superloop/boards/esp32s3_devkitc_esp32s3_procpu.overlay:52 */
				segment-offset = < 0x0 >;       /* in ../4101137-real-time-systems/firmware/superloop/boards/esp32s3_devkitc_esp32s3_procpu.overlay:53 */
				page-offset = < 0x0 >;          /* in ../4101137-real-time-systems/firmware/superloop/boards/esp32s3_devkitc_esp32s3_procpu.overlay:54 */
				display-offset = < 0x0 >;       /* in ../4101137-real-time-systems/firmware/superloop/boards/esp32s3_devkitc_esp32s3_procpu.overlay:55 */
				multiplex-ratio = < 0x3f >;     /* in ../4101137-real-time-systems/firmware/superloop/boards/esp32s3_devkitc_esp32s3_procpu.overlay:56 */
				prechargep = < 0x22 >;          /* in ../4101137-real-time-systems/firmware/superloop/boards/esp32s3_devkitc_esp32s3_procpu.overlay:57 */
				segment-remap;                  /* in ../4101137-real-time-systems/firmware/superloop/boards/esp32s3_devkitc_esp32s3_procpu.overlay:58 */
				com-invdir;                     /* in ../4101137-real-time-systems/firmware/superloop/boards/esp32s3_devkitc_esp32s3_procpu.overlay:59 */
			};
		};

		/* node '/soc/i2c@60027000' defined in zephyr/dts/xtensa/espressif/esp32s3/esp32s3_common.dtsi:315 */
		i2c1: i2c@60027000 {
			compatible = "espressif,esp32-i2c"; /* in zephyr/dts/xtensa/espressif/esp32s3/esp32s3_common.dtsi:316 */
			#address-cells = < 0x1 >;           /* in zephyr/dts/xtensa/espressif/esp32s3/esp32s3_common.dtsi:317 */
			#size-cells = < 0x0 >;              /* in zephyr/dts/xtensa/espressif/esp32s3/esp32s3_common.dtsi:318 */
			reg = < 0x60027000 0x1000 >;        /* in zephyr/dts/xtensa/espressif/esp32s3/esp32s3_common.dtsi:319 */
			interrupts = < 0x2b 0x0 0x0 >;      /* in zephyr/dts/xtensa/espressif/esp32s3/esp32s3_common.dtsi:320 */
			interrupt-parent = < &intc >;       /* in zephyr/dts/xtensa/espressif/esp32s3/esp32s3_common.dtsi:321 */
			clocks = < &clock 0x68 >;           /* in zephyr/dts/xtensa/espressif/esp32s3/esp32s3_common.dtsi:322 */
			status = "disabled";                /* in zephyr/dts/xtensa/espressif/esp32s3/esp32s3_common.dtsi:323 */
			clock-frequency = < 0x186a0 >;      /* in zephyr/boards/espressif/esp32s3_devkitc/esp32s3_devkitc_procpu.dts:83 */
			pinctrl-0 = < &i2c1_default >;      /* in zephyr/boards/espressif/esp32s3_devkitc/esp32s3_devkitc_procpu.dts:84 */
			pinctrl-names = "default";          /* in zephyr/boards/espressif/esp32s3_devkitc/esp32s3_devkitc_procpu.dts:85 */
		};

		/* node '/soc/i2s@6000f000' defined in zephyr/dts/xtensa/espressif/esp32s3/esp32s3_common.dtsi:326 */
		i2s0: i2s@6000f000 {
			compatible = "espressif,esp32-i2s"; /* in zephyr/dts/xtensa/espressif/esp32s3/esp32s3_common.dtsi:327 */
			#address-cells = < 0x1 >;           /* in zephyr/dts/xtensa/espressif/esp32s3/esp32s3_common.dtsi:328 */
			#size-cells = < 0x0 >;              /* in zephyr/dts/xtensa/espressif/esp32s3/esp32s3_common.dtsi:329 */
			reg = < 0x6000f000 0x1000 >;        /* in zephyr/dts/xtensa/espressif/esp32s3/esp32s3_common.dtsi:330 */
			interrupts = < 0x19 0x0 0x0 >;      /* in zephyr/dts/xtensa/espressif/esp32s3/esp32s3_common.dtsi:331 */
			interrupt-parent = < &intc >;       /* in zephyr/dts/xtensa/espressif/esp32s3/esp32s3_common.dtsi:332 */
			clocks = < &clock 0x69 >;           /* in zephyr/dts/xtensa/espressif/esp32s3/esp32s3_common.dtsi:333 */
			dmas = < &dma 0x2 >,
			       < &dma 0x3 >;                /* in zephyr/dts/xtensa/espressif/esp32s3/esp32s3_common.dtsi:334 */
			dma-names = "rx",
			            "tx";                   /* in zephyr/dts/xtensa/espressif/esp32s3/esp32s3_common.dtsi:335 */
			unit = < 0x0 >;                     /* in zephyr/dts/xtensa/espressif/esp32s3/esp32s3_common.dtsi:336 */
			status = "disabled";                /* in zephyr/dts/xtensa/espressif/esp32s3/esp32s3_common.dtsi:337 */
			pinctrl-0 = < &i2s0_default >;      /* in zephyr/boards/espressif/esp32s3_devkitc/esp32s3_devkitc_procpu.dts:89 */
			pinctrl-names = "default";          /* in zephyr/boards/espressif/esp32s3_devkitc/esp32s3_devkitc_procpu.dts:90 */
		};

		/* node '/soc/i2s@6002d000' defined in zephyr/dts/xtensa/espressif/esp32s3/esp32s3_common.dtsi:340 */
		i2s1: i2s@6002d000 {
			compatible = "espressif,esp32-i2s"; /* in zephyr/dts/xtensa/espressif/esp32s3/esp32s3_common.dtsi:341 */
			#address-cells = < 0x1 >;           /* in zephyr/dts/xtensa/espressif/esp32s3/esp32s3_common.dtsi:342 */
			#size-cells = < 0x0 >;              /* in zephyr/dts/xtensa/espressif/esp32s3/esp32s3_common.dtsi:343 */
			reg = < 0x6002d000 0x1000 >;        /* in zephyr/dts/xtensa/espressif/esp32s3/esp32s3_common.dtsi:344 */
			interrupts = < 0x1a 0x0 0x0 >;      /* in zephyr/dts/xtensa/espressif/esp32s3/esp32s3_common.dtsi:345 */
			interrupt-parent = < &intc >;       /* in zephyr/dts/xtensa/espressif/esp32s3/esp32s3_common.dtsi:346 */
			clocks = < &clock 0x6a >;           /* in zephyr/dts/xtensa/espressif/esp32s3/esp32s3_common.dtsi:347 */
			dmas = < &dma 0x4 >,
			       < &dma 0x5 >;                /* in zephyr/dts/xtensa/espressif/esp32s3/esp32s3_common.dtsi:348 */
			dma-names = "rx",
			            "tx";                   /* in zephyr/dts/xtensa/espressif/esp32s3/esp32s3_common.dtsi:349 */
			unit = < 0x1 >;                     /* in zephyr/dts/xtensa/espressif/esp32s3/esp32s3_common.dtsi:350 */
			status = "disabled";                /* in zephyr/dts/xtensa/espressif/esp32s3/esp32s3_common.dtsi:351 */
			pinctrl-0 = < &i2s1_default >;      /* in zephyr/boards/espressif/esp32s3_devkitc/esp32s3_devkitc_procpu.dts:94 */
			pinctrl-names = "default";          /* in zephyr/boards/espressif/esp32s3_devkitc/esp32s3_devkitc_procpu.dts:95 */
		};

		/* node '/soc/spi@60024000' defined in zephyr/dts/xtensa/espressif/esp32s3/esp32s3_common.dtsi:354 */
		spi2: spi@60024000 {
			compatible = "espressif,esp32-spi"; /* in zephyr/dts/xtensa/espressif/esp32s3/esp32s3_common.dtsi:355 */
			reg = < 0x60024000 0x1000 >;        /* in zephyr/dts/xtensa/espressif/esp32s3/esp32s3_common.dtsi:356 */
			interrupts = < 0x15 0x0 0x0 >;      /* in zephyr/dts/xtensa/espressif/esp32s3/esp32s3_common.dtsi:357 */
			interrupt-parent = < &intc >;       /* in zephyr/dts/xtensa/espressif/esp32s3/esp32s3_common.dtsi:358 */
			clocks = < &clock 0x73 >;           /* in zephyr/dts/xtensa/espressif/esp32s3/esp32s3_common.dtsi:359 */
			dma-host = < 0x0 >;                 /* in zephyr/dts/xtensa/espressif/esp32s3/esp32s3_common.dtsi:360 */
			#address-cells = < 0x1 >;           /* in zephyr/boards/espressif/esp32s3_devkitc/esp32s3_devkitc_procpu.dts:99 */
			#size-cells = < 0x0 >;              /* in zephyr/boards/espressif/esp32s3_devkitc/esp32s3_devkitc_procpu.dts:100 */
			status = "okay";                    /* in zephyr/boards/espressif/esp32s3_devkitc/esp32s3_devkitc_procpu.dts:101 */
			pinctrl-0 = < &spim2_default >;     /* in zephyr/boards/espressif/esp32s3_devkitc/esp32s3_devkitc_procpu.dts:102 */
			pinctrl-names = "default";          /* in zephyr/boards/espressif/esp32s3_devkitc/esp32s3_devkitc_procpu.dts:103 */
		};

		/* node '/soc/spi@60025000' defined in zephyr/dts/xtensa/espressif/esp32s3/esp32s3_common.dtsi:364 */
		spi3: spi@60025000 {
			compatible = "espressif,esp32-spi"; /* in zephyr/dts/xtensa/espressif/esp32s3/esp32s3_common.dtsi:365 */
			reg = < 0x60025000 0x1000 >;        /* in zephyr/dts/xtensa/espressif/esp32s3/esp32s3_common.dtsi:366 */
			interrupts = < 0x16 0x0 0x0 >;      /* in zephyr/dts/xtensa/espressif/esp32s3/esp32s3_common.dtsi:367 */
			interrupt-parent = < &intc >;       /* in zephyr/dts/xtensa/espressif/esp32s3/esp32s3_common.dtsi:368 */
			clocks = < &clock 0x74 >;           /* in zephyr/dts/xtensa/espressif/esp32s3/esp32s3_common.dtsi:369 */
			dma-host = < 0x1 >;                 /* in zephyr/dts/xtensa/espressif/esp32s3/esp32s3_common.dtsi:370 */
			#address-cells = < 0x1 >;           /* in zephyr/boards/espressif/esp32s3_devkitc/esp32s3_devkitc_procpu.dts:107 */
			#size-cells = < 0x0 >;              /* in zephyr/boards/espressif/esp32s3_devkitc/esp32s3_devkitc_procpu.dts:108 */
			status = "okay";                    /* in zephyr/boards/espressif/esp32s3_devkitc/esp32s3_devkitc_procpu.dts:109 */
			pinctrl-0 = < &spim3_default >;     /* in zephyr/boards/espressif/esp32s3_devkitc/esp32s3_devkitc_procpu.dts:110 */
			pinctrl-names = "default";          /* in zephyr/boards/espressif/esp32s3_devkitc/esp32s3_devkitc_procpu.dts:111 */
		};

		/* node '/soc/coretemp@60008800' defined in zephyr/dts/xtensa/espressif/esp32s3/esp32s3_common.dtsi:374 */
		coretemp: coretemp@60008800 {
			compatible = "espressif,esp32-temp"; /* in zephyr/dts/xtensa/espressif/esp32s3/esp32s3_common.dtsi:375 */
			friendly-name = "coretemp";          /* in zephyr/dts/xtensa/espressif/esp32s3/esp32s3_common.dtsi:376 */
			reg = < 0x60008800 0x4 >;            /* in zephyr/dts/xtensa/espressif/esp32s3/esp32s3_common.dtsi:377 */
			status = "disabled";                 /* in zephyr/dts/xtensa/espressif/esp32s3/esp32s3_common.dtsi:378 */
		};

		/* node '/soc/adc@60040000' defined in zephyr/dts/xtensa/espressif/esp32s3/esp32s3_common.dtsi:381 */
		adc0: adc@60040000 {
			compatible = "espressif,esp32-adc"; /* in zephyr/dts/xtensa/espressif/esp32s3/esp32s3_common.dtsi:382 */
			reg = < 0x60040000 0x4 >;           /* in zephyr/dts/xtensa/espressif/esp32s3/esp32s3_common.dtsi:383 */
			clocks = < &clock 0x80 >;           /* in zephyr/dts/xtensa/espressif/esp32s3/esp32s3_common.dtsi:384 */
			unit = < 0x1 >;                     /* in zephyr/dts/xtensa/espressif/esp32s3/esp32s3_common.dtsi:385 */
			channel-count = < 0xa >;            /* in zephyr/dts/xtensa/espressif/esp32s3/esp32s3_common.dtsi:386 */
			#io-channel-cells = < 0x1 >;        /* in zephyr/dts/xtensa/espressif/esp32s3/esp32s3_common.dtsi:387 */
			status = "disabled";                /* in zephyr/dts/xtensa/espressif/esp32s3/esp32s3_common.dtsi:388 */
		};

		/* node '/soc/adc@60040004' defined in zephyr/dts/xtensa/espressif/esp32s3/esp32s3_common.dtsi:391 */
		adc1: adc@60040004 {
			compatible = "espressif,esp32-adc"; /* in zephyr/dts/xtensa/espressif/esp32s3/esp32s3_common.dtsi:392 */
			reg = < 0x60040004 0x4 >;           /* in zephyr/dts/xtensa/espressif/esp32s3/esp32s3_common.dtsi:393 */
			clocks = < &clock 0x80 >;           /* in zephyr/dts/xtensa/espressif/esp32s3/esp32s3_common.dtsi:394 */
			unit = < 0x2 >;                     /* in zephyr/dts/xtensa/espressif/esp32s3/esp32s3_common.dtsi:395 */
			channel-count = < 0xa >;            /* in zephyr/dts/xtensa/espressif/esp32s3/esp32s3_common.dtsi:396 */
			#io-channel-cells = < 0x1 >;        /* in zephyr/dts/xtensa/espressif/esp32s3/esp32s3_common.dtsi:397 */
			status = "disabled";                /* in zephyr/dts/xtensa/espressif/esp32s3/esp32s3_common.dtsi:398 */
		};

		/* node '/soc/can@6002b000' defined in zephyr/dts/xtensa/espressif/esp32s3/esp32s3_common.dtsi:401 */
		twai: can@6002b000 {
			compatible = "espressif,esp32-twai"; /* in zephyr/dts/xtensa/espressif/esp32s3/esp32s3_common.dtsi:402 */
			reg = < 0x6002b000 0x1000 >;         /* in zephyr/dts/xtensa/espressif/esp32s3/esp32s3_common.dtsi:403 */
			interrupts = < 0x25 0x0 0x0 >;       /* in zephyr/dts/xtensa/espressif/esp32s3/esp32s3_common.dtsi:404 */
			interrupt-parent = < &intc >;        /* in zephyr/dts/xtensa/espressif/esp32s3/esp32s3_common.dtsi:405 */
			clocks = < &clock 0x76 >;            /* in zephyr/dts/xtensa/espressif/esp32s3/esp32s3_common.dtsi:406 */
			status = "disabled";                 /* in zephyr/dts/xtensa/espressif/esp32s3/esp32s3_common.dtsi:407 */
			pinctrl-0 = < &twai_default >;       /* in zephyr/boards/espressif/esp32s3_devkitc/esp32s3_devkitc_procpu.dts:115 */
			pinctrl-names = "default";           /* in zephyr/boards/espressif/esp32s3_devkitc/esp32s3_devkitc_procpu.dts:116 */
		};

		/* node '/soc/lcd_cam@60041000' defined in zephyr/dts/xtensa/espressif/esp32s3/esp32s3_common.dtsi:410 */
		lcd_cam: lcd_cam@60041000 {
			compatible = "espressif,esp32-lcd-cam"; /* in zephyr/dts/xtensa/espressif/esp32s3/esp32s3_common.dtsi:411 */
			reg = < 0x60041000 0x1000 >;            /* in zephyr/dts/xtensa/espressif/esp32s3/esp32s3_common.dtsi:412 */
			clocks = < &clock 0x2 >;                /* in zephyr/dts/xtensa/espressif/esp32s3/esp32s3_common.dtsi:413 */
			interrupts = < 0x18 0x0 0x0 >;          /* in zephyr/dts/xtensa/espressif/esp32s3/esp32s3_common.dtsi:414 */
			interrupt-parent = < &intc >;           /* in zephyr/dts/xtensa/espressif/esp32s3/esp32s3_common.dtsi:415 */
			dmas = < &dma 0x6 >,
			       < &dma 0x7 >;                    /* in zephyr/dts/xtensa/espressif/esp32s3/esp32s3_common.dtsi:416 */
			dma-names = "rx",
			            "tx";                       /* in zephyr/dts/xtensa/espressif/esp32s3/esp32s3_common.dtsi:417 */

			/* node '/soc/lcd_cam@60041000/lcd_cam_dvp' defined in zephyr/dts/xtensa/espressif/esp32s3/esp32s3_common.dtsi:419 */
			lcd_cam_dvp: lcd_cam_dvp {
				compatible = "espressif,esp32-lcd-cam-dvp"; /* in zephyr/dts/xtensa/espressif/esp32s3/esp32s3_common.dtsi:420 */
				status = "disabled";                        /* in zephyr/dts/xtensa/espressif/esp32s3/esp32s3_common.dtsi:421 */
			};

			/* node '/soc/lcd_cam@60041000/lcd_cam_disp' defined in zephyr/dts/xtensa/espressif/esp32s3/esp32s3_common.dtsi:424 */
			lcd_cam_disp: lcd_cam_disp {
				compatible = "espressif,esp32-lcd-cam-mipi-dbi"; /* in zephyr/dts/xtensa/espressif/esp32s3/esp32s3_common.dtsi:425 */
				#address-cells = < 0x1 >;                        /* in zephyr/dts/xtensa/espressif/esp32s3/esp32s3_common.dtsi:426 */
				#size-cells = < 0x0 >;                           /* in zephyr/dts/xtensa/espressif/esp32s3/esp32s3_common.dtsi:427 */
				status = "disabled";                             /* in zephyr/dts/xtensa/espressif/esp32s3/esp32s3_common.dtsi:428 */
			};
		};

		/* node '/soc/uart@60038000' defined in zephyr/dts/xtensa/espressif/esp32s3/esp32s3_common.dtsi:432 */
		usb_serial: uart@60038000 {
			compatible = "espressif,esp32-usb-serial"; /* in zephyr/dts/xtensa/espressif/esp32s3/esp32s3_common.dtsi:433 */
			reg = < 0x60038000 0x1000 >;               /* in zephyr/dts/xtensa/espressif/esp32s3/esp32s3_common.dtsi:434 */
			interrupts = < 0x60 0x0 0x0 >;             /* in zephyr/dts/xtensa/espressif/esp32s3/esp32s3_common.dtsi:436 */
			interrupt-parent = < &intc >;              /* in zephyr/dts/xtensa/espressif/esp32s3/esp32s3_common.dtsi:437 */
			clocks = < &clock 0x66 >;                  /* in zephyr/dts/xtensa/espressif/esp32s3/esp32s3_common.dtsi:438 */
			status = "disabled";                       /* in zephyr/boards/espressif/esp32s3_devkitc/esp32s3_devkitc_procpu.dts:46 */
		};

		/* node '/soc/usb_otg@60080000' defined in zephyr/dts/xtensa/espressif/esp32s3/esp32s3_common.dtsi:441 */
		usb_otg: zephyr_udc0: zephyr_uhc0: usb_otg@60080000 {
			compatible = "espressif,esp32-usb-otg-fs",
			             "snps,dwc2";                  /* in zephyr/dts/xtensa/espressif/esp32s3/esp32s3_common.dtsi:442 */
			reg = < 0x60080000 0x40000 >;              /* in zephyr/dts/xtensa/espressif/esp32s3/esp32s3_common.dtsi:443 */
			interrupts = < 0x26 0x0 0x0 >;             /* in zephyr/dts/xtensa/espressif/esp32s3/esp32s3_common.dtsi:445 */
			interrupt-parent = < &intc >;              /* in zephyr/dts/xtensa/espressif/esp32s3/esp32s3_common.dtsi:446 */
			clocks = < &clock 0x66 >;                  /* in zephyr/dts/xtensa/espressif/esp32s3/esp32s3_common.dtsi:447 */
			num-out-eps = < 0x6 >;                     /* in zephyr/dts/xtensa/espressif/esp32s3/esp32s3_common.dtsi:448 */
			num-in-eps = < 0x6 >;                      /* in zephyr/dts/xtensa/espressif/esp32s3/esp32s3_common.dtsi:449 */
			ghwcfg1 = < 0x0 >;                         /* in zephyr/dts/xtensa/espressif/esp32s3/esp32s3_common.dtsi:450 */
			ghwcfg2 = < 0x224dd930 >;                  /* in zephyr/dts/xtensa/espressif/esp32s3/esp32s3_common.dtsi:451 */
			ghwcfg4 = < 0xd3f0a030 >;                  /* in zephyr/dts/xtensa/espressif/esp32s3/esp32s3_common.dtsi:452 */
			phy-dp-pin = < 0x14 >;                     /* in zephyr/dts/xtensa/espressif/esp32s3/esp32s3_common.dtsi:453 */
			phy-dm-pin = < 0x13 >;                     /* in zephyr/dts/xtensa/espressif/esp32s3/esp32s3_common.dtsi:454 */
			status = "okay";                           /* in zephyr/boards/espressif/esp32s3_devkitc/esp32s3_devkitc_procpu.dts:156 */
		};

		/* node '/soc/counter@6001f000' defined in zephyr/dts/xtensa/espressif/esp32s3/esp32s3_common.dtsi:457 */
		timer0: counter@6001f000 {
			compatible = "espressif,esp32-timer"; /* in zephyr/dts/xtensa/espressif/esp32s3/esp32s3_common.dtsi:458 */
			reg = < 0x6001f000 0x1000 >;          /* in zephyr/dts/xtensa/espressif/esp32s3/esp32s3_common.dtsi:459 */
			clocks = < &clock 0x3 >;              /* in zephyr/dts/xtensa/espressif/esp32s3/esp32s3_common.dtsi:460 */
			group = < 0x0 >;                      /* in zephyr/dts/xtensa/espressif/esp32s3/esp32s3_common.dtsi:461 */
			index = < 0x0 >;                      /* in zephyr/dts/xtensa/espressif/esp32s3/esp32s3_common.dtsi:462 */
			interrupts = < 0x32 0x0 0x0 >;        /* in zephyr/dts/xtensa/espressif/esp32s3/esp32s3_common.dtsi:463 */
			interrupt-parent = < &intc >;         /* in zephyr/dts/xtensa/espressif/esp32s3/esp32s3_common.dtsi:464 */
			status = "disabled";                  /* in zephyr/boards/espressif/esp32s3_devkitc/esp32s3_devkitc_procpu.dts:120 */

			/* node '/soc/counter@6001f000/counter' defined in zephyr/dts/xtensa/espressif/esp32s3/esp32s3_common.dtsi:467 */
			counter {
				compatible = "espressif,esp32-counter"; /* in zephyr/dts/xtensa/espressif/esp32s3/esp32s3_common.dtsi:468 */
				status = "disabled";                    /* in zephyr/dts/xtensa/espressif/esp32s3/esp32s3_common.dtsi:469 */
			};
		};

		/* node '/soc/counter@6001f024' defined in zephyr/dts/xtensa/espressif/esp32s3/esp32s3_common.dtsi:473 */
		timer1: counter@6001f024 {
			compatible = "espressif,esp32-timer"; /* in zephyr/dts/xtensa/espressif/esp32s3/esp32s3_common.dtsi:474 */
			reg = < 0x6001f024 0x1000 >;          /* in zephyr/dts/xtensa/espressif/esp32s3/esp32s3_common.dtsi:475 */
			clocks = < &clock 0x3 >;              /* in zephyr/dts/xtensa/espressif/esp32s3/esp32s3_common.dtsi:476 */
			group = < 0x0 >;                      /* in zephyr/dts/xtensa/espressif/esp32s3/esp32s3_common.dtsi:477 */
			index = < 0x1 >;                      /* in zephyr/dts/xtensa/espressif/esp32s3/esp32s3_common.dtsi:478 */
			interrupts = < 0x33 0x0 0x0 >;        /* in zephyr/dts/xtensa/espressif/esp32s3/esp32s3_common.dtsi:479 */
			interrupt-parent = < &intc >;         /* in zephyr/dts/xtensa/espressif/esp32s3/esp32s3_common.dtsi:480 */
			status = "disabled";                  /* in zephyr/boards/espressif/esp32s3_devkitc/esp32s3_devkitc_procpu.dts:124 */

			/* node '/soc/counter@6001f024/counter' defined in zephyr/dts/xtensa/espressif/esp32s3/esp32s3_common.dtsi:483 */
			counter {
				compatible = "espressif,esp32-counter"; /* in zephyr/dts/xtensa/espressif/esp32s3/esp32s3_common.dtsi:484 */
				status = "disabled";                    /* in zephyr/dts/xtensa/espressif/esp32s3/esp32s3_common.dtsi:485 */
			};
		};

		/* node '/soc/counter@60020000' defined in zephyr/dts/xtensa/espressif/esp32s3/esp32s3_common.dtsi:489 */
		timer2: counter@60020000 {
			compatible = "espressif,esp32-timer"; /* in zephyr/dts/xtensa/espressif/esp32s3/esp32s3_common.dtsi:490 */
			reg = < 0x60020000 0x1000 >;          /* in zephyr/dts/xtensa/espressif/esp32s3/esp32s3_common.dtsi:491 */
			clocks = < &clock 0x4 >;              /* in zephyr/dts/xtensa/espressif/esp32s3/esp32s3_common.dtsi:492 */
			group = < 0x1 >;                      /* in zephyr/dts/xtensa/espressif/esp32s3/esp32s3_common.dtsi:493 */
			index = < 0x0 >;                      /* in zephyr/dts/xtensa/espressif/esp32s3/esp32s3_common.dtsi:494 */
			interrupts = < 0x35 0x0 0x0 >;        /* in zephyr/dts/xtensa/espressif/esp32s3/esp32s3_common.dtsi:495 */
			interrupt-parent = < &intc >;         /* in zephyr/dts/xtensa/espressif/esp32s3/esp32s3_common.dtsi:496 */
			status = "disabled";                  /* in zephyr/boards/espressif/esp32s3_devkitc/esp32s3_devkitc_procpu.dts:128 */

			/* node '/soc/counter@60020000/counter' defined in zephyr/dts/xtensa/espressif/esp32s3/esp32s3_common.dtsi:499 */
			counter {
				compatible = "espressif,esp32-counter"; /* in zephyr/dts/xtensa/espressif/esp32s3/esp32s3_common.dtsi:500 */
				status = "disabled";                    /* in zephyr/dts/xtensa/espressif/esp32s3/esp32s3_common.dtsi:501 */
			};
		};

		/* node '/soc/counter@60020024' defined in zephyr/dts/xtensa/espressif/esp32s3/esp32s3_common.dtsi:505 */
		timer3: counter@60020024 {
			compatible = "espressif,esp32-timer"; /* in zephyr/dts/xtensa/espressif/esp32s3/esp32s3_common.dtsi:506 */
			reg = < 0x60020024 0x1000 >;          /* in zephyr/dts/xtensa/espressif/esp32s3/esp32s3_common.dtsi:507 */
			clocks = < &clock 0x4 >;              /* in zephyr/dts/xtensa/espressif/esp32s3/esp32s3_common.dtsi:508 */
			group = < 0x1 >;                      /* in zephyr/dts/xtensa/espressif/esp32s3/esp32s3_common.dtsi:509 */
			index = < 0x1 >;                      /* in zephyr/dts/xtensa/espressif/esp32s3/esp32s3_common.dtsi:510 */
			interrupts = < 0x36 0x0 0x0 >;        /* in zephyr/dts/xtensa/espressif/esp32s3/esp32s3_common.dtsi:511 */
			interrupt-parent = < &intc >;         /* in zephyr/dts/xtensa/espressif/esp32s3/esp32s3_common.dtsi:512 */
			status = "disabled";                  /* in zephyr/boards/espressif/esp32s3_devkitc/esp32s3_devkitc_procpu.dts:132 */

			/* node '/soc/counter@60020024/counter' defined in zephyr/dts/xtensa/espressif/esp32s3/esp32s3_common.dtsi:514 */
			counter {
				compatible = "espressif,esp32-counter"; /* in zephyr/dts/xtensa/espressif/esp32s3/esp32s3_common.dtsi:515 */
				status = "disabled";                    /* in zephyr/dts/xtensa/espressif/esp32s3/esp32s3_common.dtsi:516 */
			};
		};

		/* node '/soc/watchdog@6001f048' defined in zephyr/dts/xtensa/espressif/esp32s3/esp32s3_common.dtsi:520 */
		wdt0: watchdog@6001f048 {
			compatible = "espressif,esp32-watchdog"; /* in zephyr/dts/xtensa/espressif/esp32s3/esp32s3_common.dtsi:521 */
			reg = < 0x6001f048 0x20 >;               /* in zephyr/dts/xtensa/espressif/esp32s3/esp32s3_common.dtsi:522 */
			interrupts = < 0x34 0x0 0x0 >;           /* in zephyr/dts/xtensa/espressif/esp32s3/esp32s3_common.dtsi:523 */
			interrupt-parent = < &intc >;            /* in zephyr/dts/xtensa/espressif/esp32s3/esp32s3_common.dtsi:524 */
			clocks = < &clock 0x3 >;                 /* in zephyr/dts/xtensa/espressif/esp32s3/esp32s3_common.dtsi:525 */
			status = "okay";                         /* in zephyr/boards/espressif/esp32s3_devkitc/esp32s3_devkitc_procpu.dts:136 */
		};

		/* node '/soc/watchdog@60020048' defined in zephyr/dts/xtensa/espressif/esp32s3/esp32s3_common.dtsi:529 */
		wdt1: watchdog@60020048 {
			compatible = "espressif,esp32-watchdog"; /* in zephyr/dts/xtensa/espressif/esp32s3/esp32s3_common.dtsi:530 */
			reg = < 0x60020048 0x20 >;               /* in zephyr/dts/xtensa/espressif/esp32s3/esp32s3_common.dtsi:531 */
			interrupts = < 0x37 0x0 0x0 >;           /* in zephyr/dts/xtensa/espressif/esp32s3/esp32s3_common.dtsi:532 */
			interrupt-parent = < &intc >;            /* in zephyr/dts/xtensa/espressif/esp32s3/esp32s3_common.dtsi:533 */
			clocks = < &clock 0x4 >;                 /* in zephyr/dts/xtensa/espressif/esp32s3/esp32s3_common.dtsi:534 */
			status = "disabled";                     /* in zephyr/dts/xtensa/espressif/esp32s3/esp32s3_common.dtsi:535 */
		};

		/* node '/soc/trng@6003507c' defined in zephyr/dts/xtensa/espressif/esp32s3/esp32s3_common.dtsi:538 */
		trng0: trng@6003507c {
			compatible = "espressif,esp32-trng"; /* in zephyr/dts/xtensa/espressif/esp32s3/esp32s3_common.dtsi:539 */
			reg = < 0x6003507c 0x4 >;            /* in zephyr/dts/xtensa/espressif/esp32s3/esp32s3_common.dtsi:540 */
			clocks = < &clock 0x6 >;             /* in zephyr/dts/xtensa/espressif/esp32s3/esp32s3_common.dtsi:541 */
			status = "okay";                     /* in zephyr/boards/espressif/esp32s3_devkitc/esp32s3_devkitc_procpu.dts:140 */
		};

		/* node '/soc/ledc@60019000' defined in zephyr/dts/xtensa/espressif/esp32s3/esp32s3_common.dtsi:545 */
		ledc0: ledc@60019000 {
			compatible = "espressif,esp32-ledc"; /* in zephyr/dts/xtensa/espressif/esp32s3/esp32s3_common.dtsi:546 */
			#pwm-cells = < 0x3 >;                /* in zephyr/dts/xtensa/espressif/esp32s3/esp32s3_common.dtsi:547 */
			reg = < 0x60019000 0x1000 >;         /* in zephyr/dts/xtensa/espressif/esp32s3/esp32s3_common.dtsi:548 */
			clocks = < &clock 0x64 >;            /* in zephyr/dts/xtensa/espressif/esp32s3/esp32s3_common.dtsi:549 */
			status = "disabled";                 /* in zephyr/dts/xtensa/espressif/esp32s3/esp32s3_common.dtsi:550 */
		};

		/* node '/soc/mcpwm@6001e000' defined in zephyr/dts/xtensa/espressif/esp32s3/esp32s3_common.dtsi:553 */
		mcpwm0: mcpwm@6001e000 {
			compatible = "espressif,esp32-mcpwm"; /* in zephyr/dts/xtensa/espressif/esp32s3/esp32s3_common.dtsi:554 */
			reg = < 0x6001e000 0x1000 >;          /* in zephyr/dts/xtensa/espressif/esp32s3/esp32s3_common.dtsi:555 */
			interrupts = < 0x1f 0x0 0x0 >;        /* in zephyr/dts/xtensa/espressif/esp32s3/esp32s3_common.dtsi:556 */
			interrupt-parent = < &intc >;         /* in zephyr/dts/xtensa/espressif/esp32s3/esp32s3_common.dtsi:557 */
			clocks = < &clock 0x6b >;             /* in zephyr/dts/xtensa/espressif/esp32s3/esp32s3_common.dtsi:558 */
			#pwm-cells = < 0x3 >;                 /* in zephyr/dts/xtensa/espressif/esp32s3/esp32s3_common.dtsi:559 */
			status = "disabled";                  /* in zephyr/dts/xtensa/espressif/esp32s3/esp32s3_common.dtsi:560 */
		};

		/* node '/soc/mcpwm@6002c000' defined in zephyr/dts/xtensa/espressif/esp32s3/esp32s3_common.dtsi:563 */
		mcpwm1: mcpwm@6002c000 {
			compatible = "espressif,esp32-mcpwm"; /* in zephyr/dts/xtensa/espressif/esp32s3/esp32s3_common.dtsi:564 */
			reg = < 0x6002c000 0x1000 >;          /* in zephyr/dts/xtensa/espressif/esp32s3/esp32s3_common.dtsi:565 */
			interrupts = < 0x20 0x0 0x0 >;        /* in zephyr/dts/xtensa/espressif/esp32s3/esp32s3_common.dtsi:566 */
			interrupt-parent = < &intc >;         /* in zephyr/dts/xtensa/espressif/esp32s3/esp32s3_common.dtsi:567 */
			clocks = < &clock 0x6c >;             /* in zephyr/dts/xtensa/espressif/esp32s3/esp32s3_common.dtsi:568 */
			#pwm-cells = < 0x3 >;                 /* in zephyr/dts/xtensa/espressif/esp32s3/esp32s3_common.dtsi:569 */
			status = "disabled";                  /* in zephyr/dts/xtensa/espressif/esp32s3/esp32s3_common.dtsi:570 */
		};

		/* node '/soc/pcnt@60017000' defined in zephyr/dts/xtensa/espressif/esp32s3/esp32s3_common.dtsi:573 */
		pcnt: pcnt@60017000 {
			compatible = "espressif,esp32-pcnt"; /* in zephyr/dts/xtensa/espressif/esp32s3/esp32s3_common.dtsi:574 */
			reg = < 0x60017000 0x1000 >;         /* in zephyr/dts/xtensa/espressif/esp32s3/esp32s3_common.dtsi:575 */
			interrupts = < 0x29 0x0 0x0 >;       /* in zephyr/dts/xtensa/espressif/esp32s3/esp32s3_common.dtsi:576 */
			interrupt-parent = < &intc >;        /* in zephyr/dts/xtensa/espressif/esp32s3/esp32s3_common.dtsi:577 */
			clocks = < &clock 0x71 >;            /* in zephyr/dts/xtensa/espressif/esp32s3/esp32s3_common.dtsi:578 */
			status = "disabled";                 /* in zephyr/dts/xtensa/espressif/esp32s3/esp32s3_common.dtsi:579 */
		};

		/* node '/soc/dma@6003f000' defined in zephyr/dts/xtensa/espressif/esp32s3/esp32s3_common.dtsi:582 */
		dma: dma@6003f000 {
			compatible = "espressif,esp32-gdma"; /* in zephyr/dts/xtensa/espressif/esp32s3/esp32s3_common.dtsi:583 */
			reg = < 0x6003f000 0x1000 >;         /* in zephyr/dts/xtensa/espressif/esp32s3/esp32s3_common.dtsi:584 */
			#dma-cells = < 0x1 >;                /* in zephyr/dts/xtensa/espressif/esp32s3/esp32s3_common.dtsi:585 */
			interrupts = < 0x42 0x0 0x100 >,
			             < 0x47 0x0 0x100 >,
			             < 0x43 0x0 0x100 >,
			             < 0x48 0x0 0x100 >,
			             < 0x44 0x0 0x100 >,
			             < 0x49 0x0 0x100 >,
			             < 0x45 0x0 0x100 >,
			             < 0x4a 0x0 0x100 >,
			             < 0x46 0x0 0x100 >,
			             < 0x4b 0x0 0x100 >;     /* in zephyr/dts/xtensa/espressif/esp32s3/esp32s3_common.dtsi:586 */
			interrupt-parent = < &intc >;        /* in zephyr/dts/xtensa/espressif/esp32s3/esp32s3_common.dtsi:606 */
			clocks = < &clock 0x7e >;            /* in zephyr/dts/xtensa/espressif/esp32s3/esp32s3_common.dtsi:607 */
			dma-channels = < 0xa >;              /* in zephyr/dts/xtensa/espressif/esp32s3/esp32s3_common.dtsi:608 */
			dma-buf-addr-alignment = < 0x4 >;    /* in zephyr/dts/xtensa/espressif/esp32s3/esp32s3_common.dtsi:609 */
			status = "disabled";                 /* in zephyr/dts/xtensa/espressif/esp32s3/esp32s3_common.dtsi:610 */
			phandle = < 0x9 >;                   /* in zephyr/dts/xtensa/espressif/esp32s3/esp32s3_common.dtsi:334 */
		};

		/* node '/soc/sdhc@60028000' defined in zephyr/dts/xtensa/espressif/esp32s3/esp32s3_common.dtsi:613 */
		sdhc: sdhc@60028000 {
			compatible = "espressif,esp32-sdhc"; /* in zephyr/dts/xtensa/espressif/esp32s3/esp32s3_common.dtsi:614 */
			reg = < 0x60028000 0x1000 >;         /* in zephyr/dts/xtensa/espressif/esp32s3/esp32s3_common.dtsi:615 */
			interrupts = < 0x1e 0x0 0x0 >;       /* in zephyr/dts/xtensa/espressif/esp32s3/esp32s3_common.dtsi:616 */
			interrupt-parent = < &intc >;        /* in zephyr/dts/xtensa/espressif/esp32s3/esp32s3_common.dtsi:617 */
			clocks = < &clock 0x75 >;            /* in zephyr/dts/xtensa/espressif/esp32s3/esp32s3_common.dtsi:618 */
			#address-cells = < 0x1 >;            /* in zephyr/dts/xtensa/espressif/esp32s3/esp32s3_common.dtsi:619 */
			#size-cells = < 0x0 >;               /* in zephyr/dts/xtensa/espressif/esp32s3/esp32s3_common.dtsi:620 */

			/* node '/soc/sdhc@60028000/sdhc@0' defined in zephyr/dts/xtensa/espressif/esp32s3/esp32s3_common.dtsi:622 */
			sdhc0: sdhc@0 {
				compatible = "espressif,esp32-sdhc-slot"; /* in zephyr/dts/xtensa/espressif/esp32s3/esp32s3_common.dtsi:623 */
				reg = < 0x0 >;                            /* in zephyr/dts/xtensa/espressif/esp32s3/esp32s3_common.dtsi:624 */
				status = "disabled";                      /* in zephyr/dts/xtensa/espressif/esp32s3/esp32s3_common.dtsi:625 */
			};

			/* node '/soc/sdhc@60028000/sdhc@1' defined in zephyr/dts/xtensa/espressif/esp32s3/esp32s3_common.dtsi:628 */
			sdhc1: sdhc@1 {
				compatible = "espressif,esp32-sdhc-slot"; /* in zephyr/dts/xtensa/espressif/esp32s3/esp32s3_common.dtsi:629 */
				reg = < 0x1 >;                            /* in zephyr/dts/xtensa/espressif/esp32s3/esp32s3_common.dtsi:630 */
				status = "disabled";                      /* in zephyr/dts/xtensa/espressif/esp32s3/esp32s3_common.dtsi:631 */
			};
		};

		/* node '/soc/sha@6003b000' defined in zephyr/dts/xtensa/espressif/esp32s3/esp32s3_common.dtsi:635 */
		sha: sha@6003b000 {
			compatible = "espressif,esp32-sha"; /* in zephyr/dts/xtensa/espressif/esp32s3/esp32s3_common.dtsi:636 */
			reg = < 0x6003b000 0x100 >;         /* in zephyr/dts/xtensa/espressif/esp32s3/esp32s3_common.dtsi:637 */
			clocks = < &clock 0x7a >;           /* in zephyr/dts/xtensa/espressif/esp32s3/esp32s3_common.dtsi:638 */
			status = "okay";                    /* in zephyr/dts/xtensa/espressif/esp32s3/esp32s3_common.dtsi:639 */
		};

		/* node '/soc/aes@6003a000' defined in zephyr/dts/xtensa/espressif/esp32s3/esp32s3_common.dtsi:642 */
		aes: aes@6003a000 {
			compatible = "espressif,esp32-aes"; /* in zephyr/dts/xtensa/espressif/esp32s3/esp32s3_common.dtsi:643 */
			reg = < 0x6003a000 0x1000 >;        /* in zephyr/dts/xtensa/espressif/esp32s3/esp32s3_common.dtsi:644 */
			clocks = < &clock 0x79 >;           /* in zephyr/dts/xtensa/espressif/esp32s3/esp32s3_common.dtsi:645 */
			status = "okay";                    /* in zephyr/dts/xtensa/espressif/esp32s3/esp32s3_common.dtsi:646 */
		};

		/* node '/soc/rmt@60016000' defined in zephyr/dts/xtensa/espressif/esp32s3/esp32s3_common.dtsi:649 */
		rmt: rmt@60016000 {
			compatible = "espressif,esp32-rmt"; /* in zephyr/dts/xtensa/espressif/esp32s3/esp32s3_common.dtsi:650 */
			#pulse-io-cells = < 0x1 >;          /* in zephyr/dts/xtensa/espressif/esp32s3/esp32s3_common.dtsi:651 */
			reg = < 0x60016000 0x1000 >;        /* in zephyr/dts/xtensa/espressif/esp32s3/esp32s3_common.dtsi:652 */
			interrupts = < 0x28 0x0 0x0 >;      /* in zephyr/dts/xtensa/espressif/esp32s3/esp32s3_common.dtsi:653 */
			interrupt-parent = < &intc >;       /* in zephyr/dts/xtensa/espressif/esp32s3/esp32s3_common.dtsi:654 */
			clocks = < &clock 0x70 >;           /* in zephyr/dts/xtensa/espressif/esp32s3/esp32s3_common.dtsi:655 */
			status = "disabled";                /* in zephyr/dts/xtensa/espressif/esp32s3/esp32s3_common.dtsi:656 */
		};
	};

	/* node '/cpus' defined in zephyr/dts/xtensa/espressif/esp32s3/esp32s3_common.dtsi:28 */
	cpus {
		#address-cells = < 0x1 >; /* in zephyr/dts/xtensa/espressif/esp32s3/esp32s3_common.dtsi:29 */
		#size-cells = < 0x0 >;    /* in zephyr/dts/xtensa/espressif/esp32s3/esp32s3_common.dtsi:30 */

		/* node '/cpus/cpu@0' defined in zephyr/dts/xtensa/espressif/esp32s3/esp32s3_common.dtsi:32 */
		cpu0: cpu@0 {
			device_type = "cpu";                             /* in zephyr/dts/xtensa/espressif/esp32s3/esp32s3_common.dtsi:33 */
			compatible = "espressif,xtensa-lx7";             /* in zephyr/dts/xtensa/espressif/esp32s3/esp32s3_common.dtsi:34 */
			reg = < 0x0 >;                                   /* in zephyr/dts/xtensa/espressif/esp32s3/esp32s3_common.dtsi:35 */
			cpu-power-states = < &light_sleep &deep_sleep >; /* in zephyr/dts/xtensa/espressif/esp32s3/esp32s3_common.dtsi:36 */
			clock-source = < 0x1 >;                          /* in zephyr/dts/xtensa/espressif/esp32s3/esp32s3_common.dtsi:37 */
			clock-frequency = < 0xe4e1c00 >;                 /* in zephyr/dts/xtensa/espressif/esp32s3/esp32s3_common.dtsi:38 */
			xtal-freq = < 0x2625a00 >;                       /* in zephyr/dts/xtensa/espressif/esp32s3/esp32s3_common.dtsi:39 */
			d-cache-line-size = < 0x10 >;                    /* in zephyr/dts/xtensa/espressif/esp32s3/esp32s3_common.dtsi:40 */
		};

		/* node '/cpus/cpu@1' defined in zephyr/dts/xtensa/espressif/esp32s3/esp32s3_common.dtsi:43 */
		cpu1: cpu@1 {
			device_type = "cpu";                 /* in zephyr/dts/xtensa/espressif/esp32s3/esp32s3_common.dtsi:44 */
			compatible = "espressif,xtensa-lx7"; /* in zephyr/dts/xtensa/espressif/esp32s3/esp32s3_common.dtsi:45 */
			reg = < 0x1 >;                       /* in zephyr/dts/xtensa/espressif/esp32s3/esp32s3_common.dtsi:46 */
			clock-source = < 0x1 >;              /* in zephyr/dts/xtensa/espressif/esp32s3/esp32s3_common.dtsi:47 */
			clock-frequency = < 0xe4e1c00 >;     /* in zephyr/dts/xtensa/espressif/esp32s3/esp32s3_common.dtsi:48 */
			xtal-freq = < 0x2625a00 >;           /* in zephyr/dts/xtensa/espressif/esp32s3/esp32s3_common.dtsi:49 */
			d-cache-line-size = < 0x10 >;        /* in zephyr/dts/xtensa/espressif/esp32s3/esp32s3_common.dtsi:50 */
		};

		/* node '/cpus/power-states' defined in zephyr/dts/xtensa/espressif/esp32s3/esp32s3_common.dtsi:53 */
		power-states {

			/* node '/cpus/power-states/light_sleep' defined in zephyr/dts/xtensa/espressif/esp32s3/esp32s3_common.dtsi:54 */
			light_sleep: light_sleep {
				compatible = "zephyr,power-state"; /* in zephyr/dts/xtensa/espressif/esp32s3/esp32s3_common.dtsi:55 */
				power-state-name = "standby";      /* in zephyr/dts/xtensa/espressif/esp32s3/esp32s3_common.dtsi:56 */
				min-residency-us = < 0x3e8 >;      /* in zephyr/dts/xtensa/espressif/esp32s3/esp32s3_common.dtsi:57 */
				exit-latency-us = < 0x0 >;         /* in zephyr/dts/xtensa/espressif/esp32s3/esp32s3_common.dtsi:58 */
				phandle = < 0xf >;                 /* in zephyr/dts/xtensa/espressif/esp32s3/esp32s3_common.dtsi:36 */
			};

			/* node '/cpus/power-states/deep_sleep' defined in zephyr/dts/xtensa/espressif/esp32s3/esp32s3_common.dtsi:61 */
			deep_sleep: deep_sleep {
				compatible = "zephyr,power-state"; /* in zephyr/dts/xtensa/espressif/esp32s3/esp32s3_common.dtsi:65 */
				power-state-name = "soft-off";     /* in zephyr/dts/xtensa/espressif/esp32s3/esp32s3_common.dtsi:66 */
				status = "disabled";               /* in zephyr/dts/xtensa/espressif/esp32s3/esp32s3_common.dtsi:67 */
				phandle = < 0x10 >;                /* in zephyr/dts/xtensa/espressif/esp32s3/esp32s3_common.dtsi:36 */
			};
		};
	};

	/* node '/wifi' defined in zephyr/dts/xtensa/espressif/esp32s3/esp32s3_common.dtsi:72 */
	wifi: wifi {
		compatible = "espressif,esp32-wifi"; /* in zephyr/dts/xtensa/espressif/esp32s3/esp32s3_common.dtsi:73 */
		status = "okay";                     /* in zephyr/boards/espressif/esp32s3_devkitc/esp32s3_devkitc_procpu.dts:148 */
	};

	/* node '/esp32_bt_hci' defined in zephyr/dts/xtensa/espressif/esp32s3/esp32s3_common.dtsi:77 */
	esp32_bt_hci: esp32_bt_hci {
		compatible = "espressif,esp32-bt-hci"; /* in zephyr/dts/xtensa/espressif/esp32s3/esp32s3_common.dtsi:78 */
		bt-hci-vs-ext;                         /* in zephyr/dts/xtensa/espressif/esp32s3/esp32s3_common.dtsi:79 */
		status = "okay";                       /* in zephyr/boards/espressif/esp32s3_devkitc/esp32s3_devkitc_procpu.dts:144 */
	};

	/* node '/pin-controller' defined in zephyr/dts/xtensa/espressif/esp32s3/esp32s3_common.dtsi:83 */
	pinctrl: pin-controller {
		compatible = "espressif,esp32-pinctrl"; /* in zephyr/dts/xtensa/espressif/esp32s3/esp32s3_common.dtsi:84 */
		status = "okay";                        /* in zephyr/dts/xtensa/espressif/esp32s3/esp32s3_common.dtsi:85 */

		/* node '/pin-controller/uart0_default' defined in zephyr/boards/espressif/esp32s3_devkitc/esp32s3_devkitc-pinctrl.dtsi:10 */
		uart0_default: uart0_default {
			phandle = < 0x4 >; /* in zephyr/boards/espressif/esp32s3_devkitc/esp32s3_devkitc_procpu.dts:52 */

			/* node '/pin-controller/uart0_default/group1' defined in zephyr/boards/espressif/esp32s3_devkitc/esp32s3_devkitc-pinctrl.dtsi:11 */
			group1 {
				pinmux = < 0x67feb >; /* in zephyr/boards/espressif/esp32s3_devkitc/esp32s3_devkitc-pinctrl.dtsi:12 */
				output-high;          /* in zephyr/boards/espressif/esp32s3_devkitc/esp32s3_devkitc-pinctrl.dtsi:13 */
			};

			/* node '/pin-controller/uart0_default/group2' defined in zephyr/boards/espressif/esp32s3_devkitc/esp32s3_devkitc-pinctrl.dtsi:16 */
			group2 {
				pinmux = < 0xff832c >; /* in zephyr/boards/espressif/esp32s3_devkitc/esp32s3_devkitc-pinctrl.dtsi:17 */
				bias-pull-up;          /* in zephyr/boards/espressif/esp32s3_devkitc/esp32s3_devkitc-pinctrl.dtsi:18 */
			};
		};

		/* node '/pin-controller/uart1_default' defined in zephyr/boards/espressif/esp32s3_devkitc/esp32s3_devkitc-pinctrl.dtsi:22 */
		uart1_default: uart1_default {

			/* node '/pin-controller/uart1_default/group1' defined in zephyr/boards/espressif/esp32s3_devkitc/esp32s3_devkitc-pinctrl.dtsi:23 */
			group1 {
				pinmux = < 0x7ffd1 >; /* in zephyr/boards/espressif/esp32s3_devkitc/esp32s3_devkitc-pinctrl.dtsi:24 */
				output-high;          /* in zephyr/boards/espressif/esp32s3_devkitc/esp32s3_devkitc-pinctrl.dtsi:25 */
			};

			/* node '/pin-controller/uart1_default/group2' defined in zephyr/boards/espressif/esp32s3_devkitc/esp32s3_devkitc-pinctrl.dtsi:28 */
			group2 {
				pinmux = < 0xff83d2 >; /* in zephyr/boards/espressif/esp32s3_devkitc/esp32s3_devkitc-pinctrl.dtsi:29 */
				bias-pull-up;          /* in zephyr/boards/espressif/esp32s3_devkitc/esp32s3_devkitc-pinctrl.dtsi:30 */
			};
		};

		/* node '/pin-controller/i2c0_default' defined in zephyr/boards/espressif/esp32s3_devkitc/esp32s3_devkitc-pinctrl.dtsi:34 */
		i2c0_default: i2c0_default {
			phandle = < 0x7 >; /* in zephyr/boards/espressif/esp32s3_devkitc/esp32s3_devkitc_procpu.dts:78 */

			/* node '/pin-controller/i2c0_default/group1' defined in zephyr/boards/espressif/esp32s3_devkitc/esp32s3_devkitc-pinctrl.dtsi:35 */
			group1 {
				pinmux = < 0x2d1681 >,
				         < 0x2c9642 >; /* in zephyr/boards/espressif/esp32s3_devkitc/esp32s3_devkitc-pinctrl.dtsi:36 */
				bias-pull-up;          /* in zephyr/boards/espressif/esp32s3_devkitc/esp32s3_devkitc-pinctrl.dtsi:38 */
				drive-open-drain;      /* in zephyr/boards/espressif/esp32s3_devkitc/esp32s3_devkitc-pinctrl.dtsi:39 */
				output-high;           /* in zephyr/boards/espressif/esp32s3_devkitc/esp32s3_devkitc-pinctrl.dtsi:40 */
			};
		};

		/* node '/pin-controller/i2c1_default' defined in zephyr/boards/espressif/esp32s3_devkitc/esp32s3_devkitc-pinctrl.dtsi:44 */
		i2c1_default: i2c1_default {
			phandle = < 0x8 >; /* in zephyr/boards/espressif/esp32s3_devkitc/esp32s3_devkitc_procpu.dts:84 */

			/* node '/pin-controller/i2c1_default/group1' defined in zephyr/boards/espressif/esp32s3_devkitc/esp32s3_devkitc-pinctrl.dtsi:45 */
			group1 {
				pinmux = < 0x2e1704 >,
				         < 0x2d96c5 >; /* in zephyr/boards/espressif/esp32s3_devkitc/esp32s3_devkitc-pinctrl.dtsi:46 */
				bias-pull-up;          /* in zephyr/boards/espressif/esp32s3_devkitc/esp32s3_devkitc-pinctrl.dtsi:48 */
				drive-open-drain;      /* in zephyr/boards/espressif/esp32s3_devkitc/esp32s3_devkitc-pinctrl.dtsi:49 */
				output-high;           /* in zephyr/boards/espressif/esp32s3_devkitc/esp32s3_devkitc-pinctrl.dtsi:50 */
			};
		};

		/* node '/pin-controller/i2s0_default' defined in zephyr/boards/espressif/esp32s3_devkitc/esp32s3_devkitc-pinctrl.dtsi:54 */
		i2s0_default: i2s0_default {
			phandle = < 0xa >; /* in zephyr/boards/espressif/esp32s3_devkitc/esp32s3_devkitc_procpu.dts:89 */

			/* node '/pin-controller/i2s0_default/group1' defined in zephyr/boards/espressif/esp32s3_devkitc/esp32s3_devkitc-pinctrl.dtsi:55 */
			group1 {
				pinmux = < 0xbffea >,
				         < 0xc0624 >,
				         < 0xb05a5 >,
				         < 0xcffe6 >,
				         < 0xff8669 >; /* in zephyr/boards/espressif/esp32s3_devkitc/esp32s3_devkitc-pinctrl.dtsi:56 */
			};
		};

		/* node '/pin-controller/i2s1_default' defined in zephyr/boards/espressif/esp32s3_devkitc/esp32s3_devkitc-pinctrl.dtsi:64 */
		i2s1_default: i2s1_default {
			phandle = < 0xb >; /* in zephyr/boards/espressif/esp32s3_devkitc/esp32s3_devkitc_procpu.dts:94 */

			/* node '/pin-controller/i2s1_default/group1' defined in zephyr/boards/espressif/esp32s3_devkitc/esp32s3_devkitc-pinctrl.dtsi:65 */
			group1 {
				pinmux = < 0xafff0 >,
				         < 0xe8744 >,
				         < 0xe0705 >,
				         < 0xf7fc6 >,
				         < 0xff878c >; /* in zephyr/boards/espressif/esp32s3_devkitc/esp32s3_devkitc-pinctrl.dtsi:66 */
			};
		};

		/* node '/pin-controller/spim2_default' defined in zephyr/boards/espressif/esp32s3_devkitc/esp32s3_devkitc-pinctrl.dtsi:74 */
		spim2_default: spim2_default {
			phandle = < 0xc >; /* in zephyr/boards/espressif/esp32s3_devkitc/esp32s3_devkitc_procpu.dts:102 */

			/* node '/pin-controller/spim2_default/group1' defined in zephyr/boards/espressif/esp32s3_devkitc/esp32s3_devkitc-pinctrl.dtsi:75 */
			group1 {
				pinmux = < 0xff998d >,
				         < 0x32ffcc >,
				         < 0x377fca >; /* in zephyr/boards/espressif/esp32s3_devkitc/esp32s3_devkitc-pinctrl.dtsi:76 */
			};

			/* node '/pin-controller/spim2_default/group2' defined in zephyr/boards/espressif/esp32s3_devkitc/esp32s3_devkitc-pinctrl.dtsi:81 */
			group2 {
				pinmux = < 0x33ffcb >; /* in zephyr/boards/espressif/esp32s3_devkitc/esp32s3_devkitc-pinctrl.dtsi:82 */
				output-low;            /* in zephyr/boards/espressif/esp32s3_devkitc/esp32s3_devkitc-pinctrl.dtsi:83 */
			};
		};

		/* node '/pin-controller/spim3_default' defined in zephyr/boards/espressif/esp32s3_devkitc/esp32s3_devkitc-pinctrl.dtsi:88 */
		spim3_default: spim3_default {
			phandle = < 0xd >; /* in zephyr/boards/espressif/esp32s3_devkitc/esp32s3_devkitc_procpu.dts:110 */

			/* node '/pin-controller/spim3_default/group1' defined in zephyr/boards/espressif/esp32s3_devkitc/esp32s3_devkitc-pinctrl.dtsi:89 */
			group1 {
				pinmux = < 0xff90e8 >,
				         < 0x217fd5 >,
				         < 0x23ffce >; /* in zephyr/boards/espressif/esp32s3_devkitc/esp32s3_devkitc-pinctrl.dtsi:90 */
			};

			/* node '/pin-controller/spim3_default/group2' defined in zephyr/boards/espressif/esp32s3_devkitc/esp32s3_devkitc-pinctrl.dtsi:95 */
			group2 {
				pinmux = < 0x227fe9 >; /* in zephyr/boards/espressif/esp32s3_devkitc/esp32s3_devkitc-pinctrl.dtsi:96 */
				output-low;            /* in zephyr/boards/espressif/esp32s3_devkitc/esp32s3_devkitc-pinctrl.dtsi:97 */
			};
		};

		/* node '/pin-controller/twai_default' defined in zephyr/boards/espressif/esp32s3_devkitc/esp32s3_devkitc-pinctrl.dtsi:101 */
		twai_default: twai_default {
			phandle = < 0xe >; /* in zephyr/boards/espressif/esp32s3_devkitc/esp32s3_devkitc_procpu.dts:115 */

			/* node '/pin-controller/twai_default/group1' defined in zephyr/boards/espressif/esp32s3_devkitc/esp32s3_devkitc-pinctrl.dtsi:102 */
			group1 {
				pinmux = < 0x3a7fc5 >,
				         < 0xff9d06 >; /* in zephyr/boards/espressif/esp32s3_devkitc/esp32s3_devkitc-pinctrl.dtsi:103 */
			};
		};

		/* node '/pin-controller/rmt_default' defined in zephyr/boards/espressif/esp32s3_devkitc/esp32s3_devkitc-pinctrl.dtsi:108 */
		rmt_default: rmt_default {

			/* node '/pin-controller/rmt_default/group1' defined in zephyr/boards/espressif/esp32s3_devkitc/esp32s3_devkitc-pinctrl.dtsi:109 */
			group1 {
				pinmux = < 0x2a7fc8 >; /* in zephyr/boards/espressif/esp32s3_devkitc/esp32s3_devkitc-pinctrl.dtsi:110 */
			};

			/* node '/pin-controller/rmt_default/group2' defined in zephyr/boards/espressif/esp32s3_devkitc/esp32s3_devkitc-pinctrl.dtsi:113 */
			group2 {
				pinmux = < 0xff9509 >; /* in zephyr/boards/espressif/esp32s3_devkitc/esp32s3_devkitc-pinctrl.dtsi:114 */
			};
		};
	};

	/* node '/clock' defined in zephyr/dts/xtensa/espressif/esp32s3/esp32s3_common.dtsi:88 */
	clock: clock {
		compatible = "espressif,esp32-clock"; /* in zephyr/dts/xtensa/espressif/esp32s3/esp32s3_common.dtsi:89 */
		fast-clk-src = < 0x1 >;               /* in zephyr/dts/xtensa/espressif/esp32s3/esp32s3_common.dtsi:90 */
		slow-clk-src = < 0x0 >;               /* in zephyr/dts/xtensa/espressif/esp32s3/esp32s3_common.dtsi:91 */
		#clock-cells = < 0x1 >;               /* in zephyr/dts/xtensa/espressif/esp32s3/esp32s3_common.dtsi:92 */
		status = "okay";                      /* in zephyr/dts/xtensa/espressif/esp32s3/esp32s3_common.dtsi:93 */
		phandle = < 0x3 >;                    /* in zephyr/dts/xtensa/espressif/esp32s3/esp32s3_common.dtsi:200 */
	};

	/* node '/buttons' defined in zephyr/boards/espressif/esp32s3_devkitc/esp32s3_devkitc_procpu.dts:34 */
	buttons {
		compatible = "gpio-keys"; /* in zephyr/boards/espressif/esp32s3_devkitc/esp32s3_devkitc_procpu.dts:35 */

		/* node '/buttons/button_0' defined in zephyr/boards/espressif/esp32s3_devkitc/esp32s3_devkitc_procpu.dts:37 */
		button0: button_0 {
			gpios = < &gpio0 0x0 0x11 >; /* in zephyr/boards/espressif/esp32s3_devkitc/esp32s3_devkitc_procpu.dts:38 */
			label = "BOOT Button";       /* in zephyr/boards/espressif/esp32s3_devkitc/esp32s3_devkitc_procpu.dts:39 */
			zephyr,code = < 0xb >;       /* in zephyr/boards/espressif/esp32s3_devkitc/esp32s3_devkitc_procpu.dts:40 */
		};
	};

	/* node '/leds' defined in ../4101137-real-time-systems/firmware/superloop/boards/esp32s3_devkitc_esp32s3_procpu.overlay:19 */
	leds {
		compatible = "gpio-leds"; /* in ../4101137-real-time-systems/firmware/superloop/boards/esp32s3_devkitc_esp32s3_procpu.overlay:20 */

		/* node '/leds/valve_out' defined in ../4101137-real-time-systems/firmware/superloop/boards/esp32s3_devkitc_esp32s3_procpu.overlay:21 */
		valve_out: valve_out {
			gpios = < &gpio0 0x15 0x0 >; /* in ../4101137-real-time-systems/firmware/superloop/boards/esp32s3_devkitc_esp32s3_procpu.overlay:21 */
		};
	};

	/* node '/instr' defined in ../4101137-real-time-systems/firmware/superloop/boards/esp32s3_devkitc_esp32s3_procpu.overlay:24 */
	instr {
		compatible = "gpio-leds"; /* in ../4101137-real-time-systems/firmware/superloop/boards/esp32s3_devkitc_esp32s3_procpu.overlay:25 */

		/* node '/instr/instr_samp' defined in ../4101137-real-time-systems/firmware/superloop/boards/esp32s3_devkitc_esp32s3_procpu.overlay:26 */
		instr_samp: instr_samp {
			gpios = < &gpio0 0x4 0x0 >; /* in ../4101137-real-time-systems/firmware/superloop/boards/esp32s3_devkitc_esp32s3_procpu.overlay:26 */
		};

		/* node '/instr/instr_ctrl' defined in ../4101137-real-time-systems/firmware/superloop/boards/esp32s3_devkitc_esp32s3_procpu.overlay:27 */
		instr_ctrl: instr_ctrl {
			gpios = < &gpio0 0x5 0x0 >; /* in ../4101137-real-time-systems/firmware/superloop/boards/esp32s3_devkitc_esp32s3_procpu.overlay:27 */
		};

		/* node '/instr/instr_cons' defined in ../4101137-real-time-systems/firmware/superloop/boards/esp32s3_devkitc_esp32s3_procpu.overlay:28 */
		instr_cons: instr_cons {
			gpios = < &gpio0 0x6 0x0 >; /* in ../4101137-real-time-systems/firmware/superloop/boards/esp32s3_devkitc_esp32s3_procpu.overlay:28 */
		};

		/* node '/instr/instr_tele' defined in ../4101137-real-time-systems/firmware/superloop/boards/esp32s3_devkitc_esp32s3_procpu.overlay:29 */
		instr_tele: instr_tele {
			gpios = < &gpio0 0x7 0x0 >; /* in ../4101137-real-time-systems/firmware/superloop/boards/esp32s3_devkitc_esp32s3_procpu.overlay:29 */
		};

		/* node '/instr/instr_flow' defined in ../4101137-real-time-systems/firmware/superloop/boards/esp32s3_devkitc_esp32s3_procpu.overlay:30 */
		instr_flow: instr_flow {
			gpios = < &gpio0 0xf 0x0 >; /* in ../4101137-real-time-systems/firmware/superloop/boards/esp32s3_devkitc_esp32s3_procpu.overlay:30 */
		};

		/* node '/instr/instr_disp' defined in ../4101137-real-time-systems/firmware/superloop/boards/esp32s3_devkitc_esp32s3_procpu.overlay:31 */
		instr_disp: instr_disp {
			gpios = < &gpio0 0x11 0x0 >; /* in ../4101137-real-time-systems/firmware/superloop/boards/esp32s3_devkitc_esp32s3_procpu.overlay:31 */
		};
	};

	/* node '/keys' defined in ../4101137-real-time-systems/firmware/superloop/boards/esp32s3_devkitc_esp32s3_procpu.overlay:34 */
	keys {
		compatible = "gpio-keys"; /* in ../4101137-real-time-systems/firmware/superloop/boards/esp32s3_devkitc_esp32s3_procpu.overlay:35 */

		/* node '/keys/flow_pulse' defined in ../4101137-real-time-systems/firmware/superloop/boards/esp32s3_devkitc_esp32s3_procpu.overlay:36 */
		flow_pulse: flow_pulse {
			gpios = < &gpio0 0x10 0x20 >; /* in ../4101137-real-time-systems/firmware/superloop/boards/esp32s3_devkitc_esp32s3_procpu.overlay:37 */
		};
	};
};
